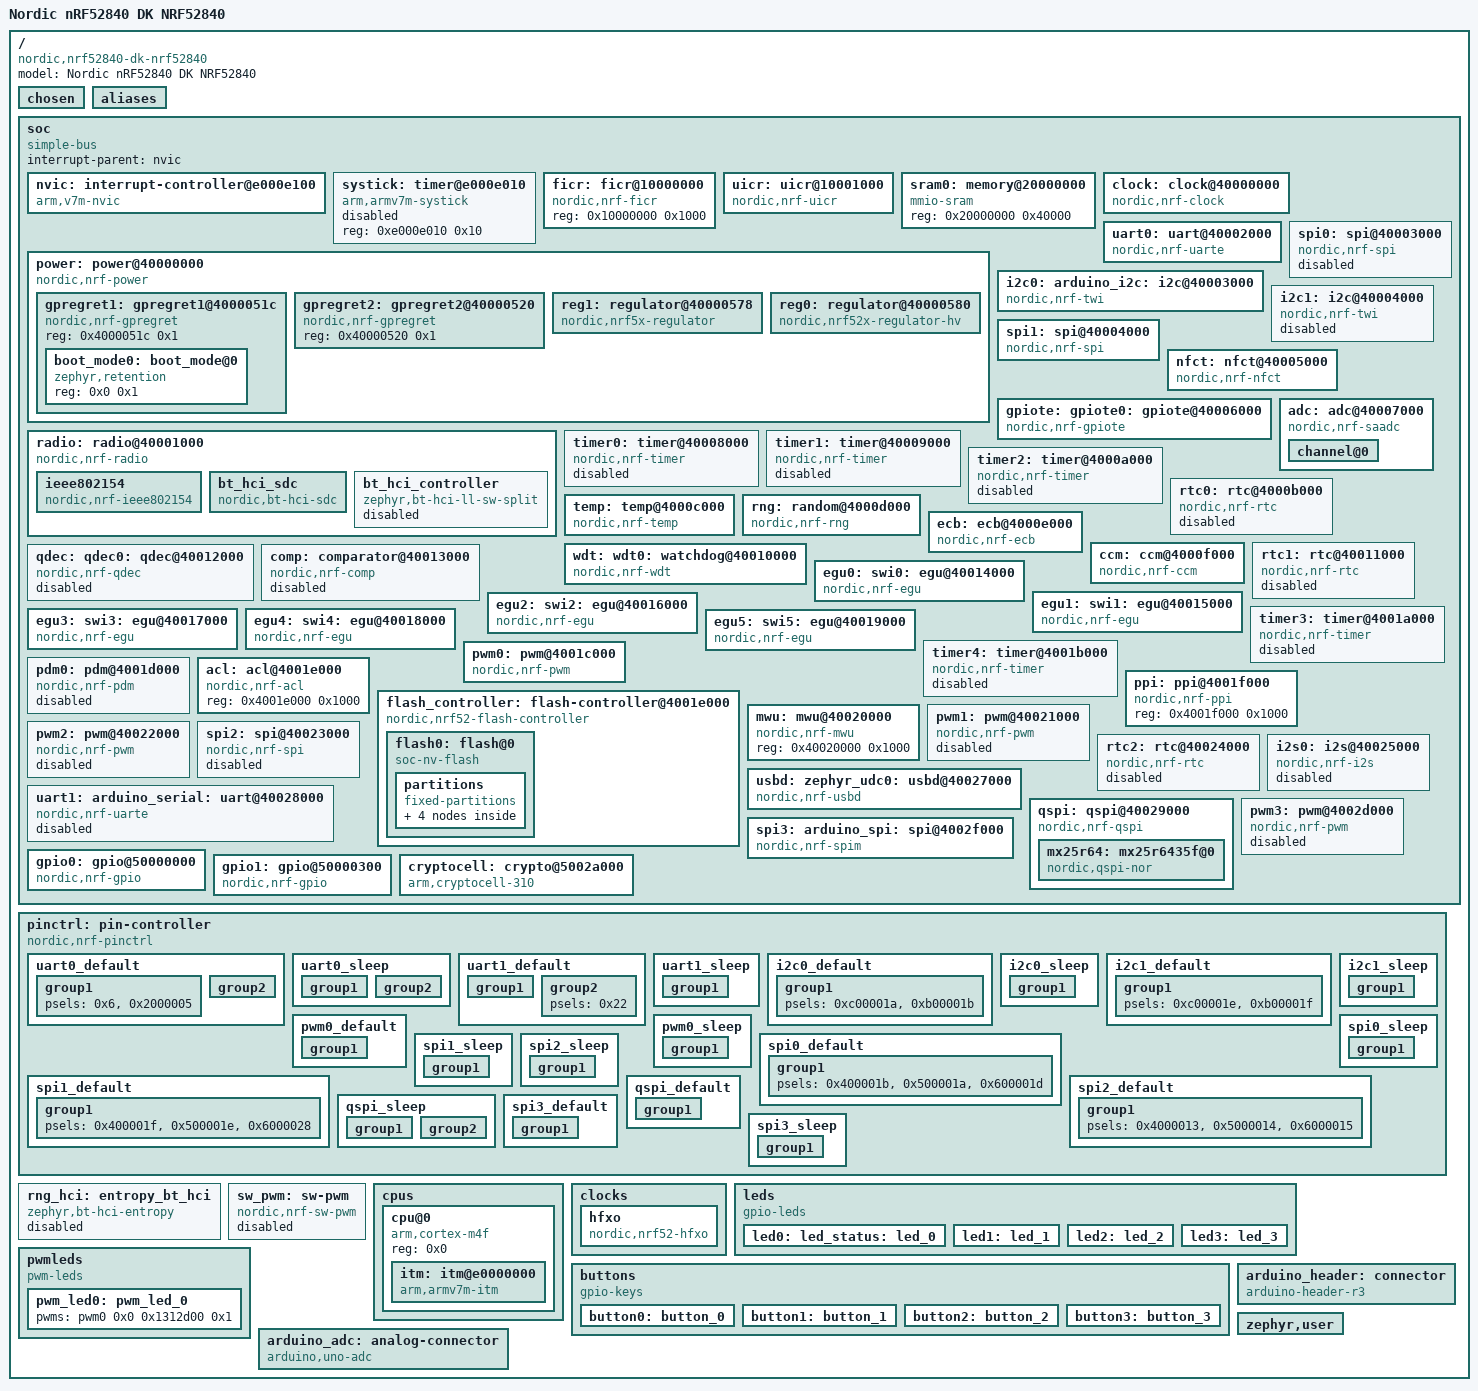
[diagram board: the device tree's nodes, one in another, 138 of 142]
/dts-v1/;

/* node '/' defined in zephyr\dts\common\skeleton.dtsi:9 */
/ {
	#address-cells = < 0x1 >;                   /* in zephyr\dts\common\skeleton.dtsi:10 */
	#size-cells = < 0x1 >;                      /* in zephyr\dts\common\skeleton.dtsi:11 */
	model = "Nordic nRF52840 DK NRF52840";      /* in zephyr\boards\nordic\nrf52840dk\nrf52840dk_nrf52840.dts:15 */
	compatible = "nordic,nrf52840-dk-nrf52840"; /* in zephyr\boards\nordic\nrf52840dk\nrf52840dk_nrf52840.dts:16 */

	/* node '/chosen' defined in zephyr\dts\common\skeleton.dtsi:13 */
	chosen {
		zephyr,bt-hci = &bt_hci_sdc;                 /* in zephyr\dts\arm\nordic\nrf52840.dtsi:14 */
		zephyr,entropy = &cryptocell;                /* in zephyr\dts\arm\nordic\nrf52840.dtsi:15 */
		zephyr,flash-controller = &flash_controller; /* in zephyr\dts\arm\nordic\nrf52840.dtsi:16 */
		zephyr,sram = &sram0;                        /* in zephyr\dts\vendor\nordic\nrf52840_partition.dtsi:9 */
		zephyr,flash = &flash0;                      /* in zephyr\dts\vendor\nordic\nrf52840_partition.dtsi:10 */
		zephyr,code-partition = &slot0_partition;    /* in zephyr\dts\vendor\nordic\nrf52840_partition.dtsi:11 */
		zephyr,console = &uart0;                     /* in zephyr\boards\nordic\nrf52840dk\nrf52840dk_nrf52840.dts:19 */
		zephyr,shell-uart = &uart0;                  /* in zephyr\boards\nordic\nrf52840dk\nrf52840dk_nrf52840.dts:20 */
		zephyr,uart-mcumgr = &uart0;                 /* in zephyr\boards\nordic\nrf52840dk\nrf52840dk_nrf52840.dts:21 */
		zephyr,bt-mon-uart = &uart0;                 /* in zephyr\boards\nordic\nrf52840dk\nrf52840dk_nrf52840.dts:22 */
		zephyr,bt-c2h-uart = &uart0;                 /* in zephyr\boards\nordic\nrf52840dk\nrf52840dk_nrf52840.dts:23 */
		zephyr,ieee802154 = &ieee802154;             /* in zephyr\boards\nordic\nrf52840dk\nrf52840dk_nrf52840.dts:24 */
		zephyr,boot-mode = &boot_mode0;              /* in zephyr\boards\nordic\nrf52840dk\nrf52840dk_nrf52840.dts:25 */
	};

	/* node '/aliases' defined in zephyr\dts\common\skeleton.dtsi:15 */
	aliases {
		led0 = &led0;               /* in zephyr\boards\nordic\nrf52840dk\nrf52840dk_nrf52840.dts:130 */
		led1 = &led1;               /* in zephyr\boards\nordic\nrf52840dk\nrf52840dk_nrf52840.dts:131 */
		led2 = &led2;               /* in zephyr\boards\nordic\nrf52840dk\nrf52840dk_nrf52840.dts:132 */
		led3 = &led3;               /* in zephyr\boards\nordic\nrf52840dk\nrf52840dk_nrf52840.dts:133 */
		pwm-led0 = &pwm_led0;       /* in zephyr\boards\nordic\nrf52840dk\nrf52840dk_nrf52840.dts:134 */
		sw0 = &button0;             /* in zephyr\boards\nordic\nrf52840dk\nrf52840dk_nrf52840.dts:135 */
		sw1 = &button1;             /* in zephyr\boards\nordic\nrf52840dk\nrf52840dk_nrf52840.dts:136 */
		sw2 = &button2;             /* in zephyr\boards\nordic\nrf52840dk\nrf52840dk_nrf52840.dts:137 */
		sw3 = &button3;             /* in zephyr\boards\nordic\nrf52840dk\nrf52840dk_nrf52840.dts:138 */
		mcuboot-button0 = &button0; /* in zephyr\boards\nordic\nrf52840dk\nrf52840dk_nrf52840.dts:139 */
		mcuboot-led0 = &led0;       /* in zephyr\boards\nordic\nrf52840dk\nrf52840dk_nrf52840.dts:140 */
		watchdog0 = &wdt0;          /* in zephyr\boards\nordic\nrf52840dk\nrf52840dk_nrf52840.dts:141 */
		led-status = &led_status;   /* in ..\..\Users\willh\Desktop\Fish_monitor\aquatic_biomonitor_fw\boards\nrf52840dk_nrf52840.overlay:16 */
	};

	/* node '/soc' defined in zephyr\dts\arm\armv7-m.dtsi:6 */
	soc {
		#address-cells = < 0x1 >;     /* in zephyr\dts\arm\armv7-m.dtsi:7 */
		#size-cells = < 0x1 >;        /* in zephyr\dts\arm\armv7-m.dtsi:8 */
		interrupt-parent = < &nvic >; /* in zephyr\dts\arm\armv7-m.dtsi:10 */
		ranges;                       /* in zephyr\dts\arm\armv7-m.dtsi:11 */
		compatible = "simple-bus";    /* in zephyr\dts\arm\nordic\nrf52840.dtsi:48 */

		/* node '/soc/interrupt-controller@e000e100' defined in zephyr\dts\arm\armv7-m.dtsi:13 */
		nvic: interrupt-controller@e000e100 {
			#address-cells = < 0x1 >;            /* in zephyr\dts\arm\armv7-m.dtsi:14 */
			compatible = "arm,v7m-nvic";         /* in zephyr\dts\arm\armv7-m.dtsi:15 */
			reg = < 0xe000e100 0xc00 >;          /* in zephyr\dts\arm\armv7-m.dtsi:16 */
			interrupt-controller;                /* in zephyr\dts\arm\armv7-m.dtsi:17 */
			#interrupt-cells = < 0x2 >;          /* in zephyr\dts\arm\armv7-m.dtsi:18 */
			arm,num-irq-priority-bits = < 0x3 >; /* in zephyr\dts\arm\nordic\nrf52840.dtsi:599 */
			phandle = < 0x1 >;                   /* in zephyr\dts\arm\armv7-m.dtsi:10 */
		};

		/* node '/soc/timer@e000e010' defined in zephyr\dts\arm\armv7-m.dtsi:21 */
		systick: timer@e000e010 {
			compatible = "arm,armv7m-systick"; /* in zephyr\dts\arm\armv7-m.dtsi:22 */
			reg = < 0xe000e010 0x10 >;         /* in zephyr\dts\arm\armv7-m.dtsi:23 */
			status = "disabled";               /* in zephyr\dts\arm\nordic\nrf52840.dtsi:604 */
		};

		/* node '/soc/ficr@10000000' defined in zephyr\dts\arm\nordic\nrf52840.dtsi:50 */
		ficr: ficr@10000000 {
			compatible = "nordic,nrf-ficr"; /* in zephyr\dts\arm\nordic\nrf52840.dtsi:51 */
			reg = < 0x10000000 0x1000 >;    /* in zephyr\dts\arm\nordic\nrf52840.dtsi:52 */
			#nordic,ficr-cells = < 0x1 >;   /* in zephyr\dts\arm\nordic\nrf52840.dtsi:53 */
			status = "okay";                /* in zephyr\dts\arm\nordic\nrf52840.dtsi:54 */
		};

		/* node '/soc/uicr@10001000' defined in zephyr\dts\arm\nordic\nrf52840.dtsi:57 */
		uicr: uicr@10001000 {
			compatible = "nordic,nrf-uicr";     /* in zephyr\dts\arm\nordic\nrf52840.dtsi:58 */
			reg = < 0x10001000 0x1000 >;        /* in zephyr\dts\arm\nordic\nrf52840.dtsi:59 */
			ranges = < 0x0 0x10001000 0x1000 >; /* in zephyr\dts\arm\nordic\nrf52840.dtsi:60 */
			status = "okay";                    /* in zephyr\dts\arm\nordic\nrf52840.dtsi:61 */
			#address-cells = < 0x1 >;           /* in zephyr\dts\arm\nordic\nrf52840.dtsi:62 */
			#size-cells = < 0x1 >;              /* in zephyr\dts\arm\nordic\nrf52840.dtsi:63 */
			gpio-as-nreset;                     /* in zephyr\boards\nordic\nrf52840dk\nrf52840dk_nrf52840.dts:158 */
		};

		/* node '/soc/memory@20000000' defined in zephyr\dts\arm\nordic\nrf52840.dtsi:66 */
		sram0: memory@20000000 {
			compatible = "mmio-sram";            /* in zephyr\dts\arm\nordic\nrf52840.dtsi:67 */
			reg = < 0x20000000 0x40000 >;        /* in zephyr\dts\arm\nordic\nrf52840.dtsi:68 */
			ranges = < 0x0 0x20000000 0x40000 >; /* in zephyr\dts\arm\nordic\nrf52840.dtsi:69 */
			#address-cells = < 0x1 >;            /* in zephyr\dts\arm\nordic\nrf52840.dtsi:70 */
			#size-cells = < 0x1 >;               /* in zephyr\dts\arm\nordic\nrf52840.dtsi:71 */
		};

		/* node '/soc/clock@40000000' defined in zephyr\dts\arm\nordic\nrf52840.dtsi:74 */
		clock: clock@40000000 {
			compatible = "nordic,nrf-clock"; /* in zephyr\dts\arm\nordic\nrf52840.dtsi:75 */
			reg = < 0x40000000 0x1000 >;     /* in zephyr\dts\arm\nordic\nrf52840.dtsi:76 */
			interrupts = < 0x0 0x1 >;        /* in zephyr\dts\arm\nordic\nrf52840.dtsi:77 */
			status = "okay";                 /* in zephyr\dts\arm\nordic\nrf52840.dtsi:78 */
		};

		/* node '/soc/power@40000000' defined in zephyr\dts\arm\nordic\nrf52840.dtsi:81 */
		power: power@40000000 {
			compatible = "nordic,nrf-power"; /* in zephyr\dts\arm\nordic\nrf52840.dtsi:82 */
			reg = < 0x40000000 0x1000 >;     /* in zephyr\dts\arm\nordic\nrf52840.dtsi:83 */
			interrupts = < 0x0 0x1 >;        /* in zephyr\dts\arm\nordic\nrf52840.dtsi:84 */
			status = "okay";                 /* in zephyr\dts\arm\nordic\nrf52840.dtsi:85 */
			#address-cells = < 0x1 >;        /* in zephyr\dts\arm\nordic\nrf52840.dtsi:86 */
			#size-cells = < 0x1 >;           /* in zephyr\dts\arm\nordic\nrf52840.dtsi:87 */

			/* node '/soc/power@40000000/gpregret1@4000051c' defined in zephyr\dts\arm\nordic\nrf52840.dtsi:89 */
			gpregret1: gpregret1@4000051c {
				#address-cells = < 0x1 >;           /* in zephyr\dts\arm\nordic\nrf52840.dtsi:90 */
				#size-cells = < 0x1 >;              /* in zephyr\dts\arm\nordic\nrf52840.dtsi:91 */
				compatible = "nordic,nrf-gpregret"; /* in zephyr\dts\arm\nordic\nrf52840.dtsi:92 */
				reg = < 0x4000051c 0x1 >;           /* in zephyr\dts\arm\nordic\nrf52840.dtsi:93 */
				status = "okay";                    /* in zephyr\boards\nordic\nrf52840dk\nrf52840dk_nrf52840.dts:294 */

				/* node '/soc/power@40000000/gpregret1@4000051c/boot_mode@0' defined in zephyr\boards\nordic\nrf52840dk\nrf52840dk_nrf52840.dts:296 */
				boot_mode0: boot_mode@0 {
					compatible = "zephyr,retention"; /* in zephyr\boards\nordic\nrf52840dk\nrf52840dk_nrf52840.dts:297 */
					status = "okay";                 /* in zephyr\boards\nordic\nrf52840dk\nrf52840dk_nrf52840.dts:298 */
					reg = < 0x0 0x1 >;               /* in zephyr\boards\nordic\nrf52840dk\nrf52840dk_nrf52840.dts:299 */
				};
			};

			/* node '/soc/power@40000000/gpregret2@40000520' defined in zephyr\dts\arm\nordic\nrf52840.dtsi:97 */
			gpregret2: gpregret2@40000520 {
				#address-cells = < 0x1 >;           /* in zephyr\dts\arm\nordic\nrf52840.dtsi:98 */
				#size-cells = < 0x1 >;              /* in zephyr\dts\arm\nordic\nrf52840.dtsi:99 */
				compatible = "nordic,nrf-gpregret"; /* in zephyr\dts\arm\nordic\nrf52840.dtsi:100 */
				reg = < 0x40000520 0x1 >;           /* in zephyr\dts\arm\nordic\nrf52840.dtsi:101 */
				status = "okay";                    /* in zephyr\dts\arm\nordic\nrf52840.dtsi:102 */
			};

			/* node '/soc/power@40000000/regulator@40000578' defined in zephyr\dts\arm\nordic\nrf52840.dtsi:105 */
			reg1: regulator@40000578 {
				compatible = "nordic,nrf5x-regulator"; /* in zephyr\dts\arm\nordic\nrf52840.dtsi:106 */
				reg = < 0x40000578 0x1 >;              /* in zephyr\dts\arm\nordic\nrf52840.dtsi:107 */
				regulator-name = "REG1";               /* in zephyr\dts\arm\nordic\nrf52840.dtsi:108 */
				regulator-initial-mode = < 0x1 >;      /* in zephyr\boards\nordic\nrf52840dk\nrf52840dk_nrf52840.dts:150 */
			};

			/* node '/soc/power@40000000/regulator@40000580' defined in zephyr\dts\arm\nordic\nrf52840_qiaa.dtsi:11 */
			reg0: regulator@40000580 {
				compatible = "nordic,nrf52x-regulator-hv"; /* in zephyr\dts\arm\nordic\nrf52840_qiaa.dtsi:12 */
				reg = < 0x40000580 0x1 >;                  /* in zephyr\dts\arm\nordic\nrf52840_qiaa.dtsi:13 */
				regulator-name = "REG0";                   /* in zephyr\dts\arm\nordic\nrf52840_qiaa.dtsi:14 */
				status = "okay";                           /* in zephyr\boards\nordic\nrf52840dk\nrf52840dk_nrf52840.dts:146 */
			};
		};

		/* node '/soc/radio@40001000' defined in zephyr\dts\arm\nordic\nrf52840.dtsi:113 */
		radio: radio@40001000 {
			compatible = "nordic,nrf-radio"; /* in zephyr\dts\arm\nordic\nrf52840.dtsi:114 */
			reg = < 0x40001000 0x1000 >;     /* in zephyr\dts\arm\nordic\nrf52840.dtsi:115 */
			interrupts = < 0x1 0x1 >;        /* in zephyr\dts\arm\nordic\nrf52840.dtsi:116 */
			status = "okay";                 /* in zephyr\dts\arm\nordic\nrf52840.dtsi:117 */
			ieee802154-supported;            /* in zephyr\dts\arm\nordic\nrf52840.dtsi:118 */
			ble-2mbps-supported;             /* in zephyr\dts\arm\nordic\nrf52840.dtsi:119 */
			ble-coded-phy-supported;         /* in zephyr\dts\arm\nordic\nrf52840.dtsi:120 */
			radio-tx-high-power-supported;   /* in zephyr\dts\arm\nordic\nrf52840.dtsi:121 */

			/* node '/soc/radio@40001000/ieee802154' defined in zephyr\dts\arm\nordic\nrf52840.dtsi:123 */
			ieee802154: ieee802154 {
				compatible = "nordic,nrf-ieee802154"; /* in zephyr\dts\arm\nordic\nrf52840.dtsi:124 */
				status = "okay";                      /* in zephyr\boards\nordic\nrf52840dk\nrf52840dk_nrf52840.dts:285 */
			};

			/* node '/soc/radio@40001000/bt_hci_sdc' defined in zephyr\dts\arm\nordic\nrf52840.dtsi:128 */
			bt_hci_sdc: bt_hci_sdc {
				compatible = "nordic,bt-hci-sdc"; /* in zephyr\dts\arm\nordic\nrf52840.dtsi:129 */
				status = "okay";                  /* in zephyr\dts\arm\nordic\nrf52840.dtsi:130 */
			};

			/* node '/soc/radio@40001000/bt_hci_controller' defined in zephyr\dts\arm\nordic\nrf52840.dtsi:132 */
			bt_hci_controller: bt_hci_controller {
				compatible = "zephyr,bt-hci-ll-sw-split"; /* in zephyr\dts\arm\nordic\nrf52840.dtsi:133 */
				status = "disabled";                      /* in zephyr\dts\arm\nordic\nrf52840.dtsi:134 */
			};
		};

		/* node '/soc/uart@40002000' defined in zephyr\dts\arm\nordic\nrf52840.dtsi:138 */
		uart0: uart@40002000 {
			reg = < 0x40002000 0x1000 >;     /* in zephyr\dts\arm\nordic\nrf52840.dtsi:142 */
			interrupts = < 0x2 0x1 >;        /* in zephyr\dts\arm\nordic\nrf52840.dtsi:143 */
			compatible = "nordic,nrf-uarte"; /* in zephyr\boards\nordic\nrf52840dk\nrf52840dk_nrf52840.dts:186 */
			status = "okay";                 /* in zephyr\boards\nordic\nrf52840dk\nrf52840dk_nrf52840.dts:187 */
			current-speed = < 0x1c200 >;     /* in zephyr\boards\nordic\nrf52840dk\nrf52840dk_nrf52840.dts:188 */
			pinctrl-0 = < &uart0_default >;  /* in zephyr\boards\nordic\nrf52840dk\nrf52840dk_nrf52840.dts:189 */
			pinctrl-1 = < &uart0_sleep >;    /* in zephyr\boards\nordic\nrf52840dk\nrf52840dk_nrf52840.dts:190 */
			pinctrl-names = "default",
			                "sleep";         /* in zephyr\boards\nordic\nrf52840dk\nrf52840dk_nrf52840.dts:191 */
		};

		/* node '/soc/i2c@40003000' defined in zephyr\dts\arm\nordic\nrf52840.dtsi:147 */
		i2c0: arduino_i2c: i2c@40003000 {
			#address-cells = < 0x1 >;       /* in zephyr\dts\arm\nordic\nrf52840.dtsi:156 */
			#size-cells = < 0x0 >;          /* in zephyr\dts\arm\nordic\nrf52840.dtsi:157 */
			reg = < 0x40003000 0x1000 >;    /* in zephyr\dts\arm\nordic\nrf52840.dtsi:158 */
			interrupts = < 0x3 0x1 >;       /* in zephyr\dts\arm\nordic\nrf52840.dtsi:159 */
			easydma-maxcnt-bits = < 0x10 >; /* in zephyr\dts\arm\nordic\nrf52840.dtsi:160 */
			zephyr,pm-device-runtime-auto;  /* in zephyr\dts\arm\nordic\nrf52840.dtsi:162 */
			compatible = "nordic,nrf-twi";  /* in zephyr\boards\nordic\nrf52840dk\nrf52840dk_nrf52840.dts:202 */
			status = "okay";                /* in zephyr\boards\nordic\nrf52840dk\nrf52840dk_nrf52840.dts:203 */
			pinctrl-0 = < &i2c0_default >;  /* in zephyr\boards\nordic\nrf52840dk\nrf52840dk_nrf52840.dts:204 */
			pinctrl-1 = < &i2c0_sleep >;    /* in zephyr\boards\nordic\nrf52840dk\nrf52840dk_nrf52840.dts:205 */
			pinctrl-names = "default",
			                "sleep";        /* in zephyr\boards\nordic\nrf52840dk\nrf52840dk_nrf52840.dts:206 */
		};

		/* node '/soc/spi@40003000' defined in zephyr\dts\arm\nordic\nrf52840.dtsi:165 */
		spi0: spi@40003000 {
			#address-cells = < 0x1 >;       /* in zephyr\dts\arm\nordic\nrf52840.dtsi:174 */
			#size-cells = < 0x0 >;          /* in zephyr\dts\arm\nordic\nrf52840.dtsi:175 */
			reg = < 0x40003000 0x1000 >;    /* in zephyr\dts\arm\nordic\nrf52840.dtsi:176 */
			interrupts = < 0x3 0x1 >;       /* in zephyr\dts\arm\nordic\nrf52840.dtsi:177 */
			max-frequency = < 0x7a1200 >;   /* in zephyr\dts\arm\nordic\nrf52840.dtsi:178 */
			easydma-maxcnt-bits = < 0x10 >; /* in zephyr\dts\arm\nordic\nrf52840.dtsi:179 */
			status = "disabled";            /* in zephyr\dts\arm\nordic\nrf52840.dtsi:180 */
			compatible = "nordic,nrf-spi";  /* in zephyr\boards\nordic\nrf52840dk\nrf52840dk_nrf52840.dts:226 */
			pinctrl-0 = < &spi0_default >;  /* in zephyr\boards\nordic\nrf52840dk\nrf52840dk_nrf52840.dts:229 */
			pinctrl-1 = < &spi0_sleep >;    /* in zephyr\boards\nordic\nrf52840dk\nrf52840dk_nrf52840.dts:230 */
			pinctrl-names = "default",
			                "sleep";        /* in zephyr\boards\nordic\nrf52840dk\nrf52840dk_nrf52840.dts:231 */
		};

		/* node '/soc/i2c@40004000' defined in zephyr\dts\arm\nordic\nrf52840.dtsi:183 */
		i2c1: i2c@40004000 {
			#address-cells = < 0x1 >;       /* in zephyr\dts\arm\nordic\nrf52840.dtsi:192 */
			#size-cells = < 0x0 >;          /* in zephyr\dts\arm\nordic\nrf52840.dtsi:193 */
			reg = < 0x40004000 0x1000 >;    /* in zephyr\dts\arm\nordic\nrf52840.dtsi:194 */
			interrupts = < 0x4 0x1 >;       /* in zephyr\dts\arm\nordic\nrf52840.dtsi:195 */
			easydma-maxcnt-bits = < 0x10 >; /* in zephyr\dts\arm\nordic\nrf52840.dtsi:196 */
			status = "disabled";            /* in zephyr\dts\arm\nordic\nrf52840.dtsi:197 */
			zephyr,pm-device-runtime-auto;  /* in zephyr\dts\arm\nordic\nrf52840.dtsi:198 */
			compatible = "nordic,nrf-twi";  /* in zephyr\boards\nordic\nrf52840dk\nrf52840dk_nrf52840.dts:210 */
			pinctrl-0 = < &i2c1_default >;  /* in zephyr\boards\nordic\nrf52840dk\nrf52840dk_nrf52840.dts:213 */
			pinctrl-1 = < &i2c1_sleep >;    /* in zephyr\boards\nordic\nrf52840dk\nrf52840dk_nrf52840.dts:214 */
			pinctrl-names = "default",
			                "sleep";        /* in zephyr\boards\nordic\nrf52840dk\nrf52840dk_nrf52840.dts:215 */
		};

		/* node '/soc/spi@40004000' defined in zephyr\dts\arm\nordic\nrf52840.dtsi:201 */
		spi1: spi@40004000 {
			#address-cells = < 0x1 >;       /* in zephyr\dts\arm\nordic\nrf52840.dtsi:210 */
			#size-cells = < 0x0 >;          /* in zephyr\dts\arm\nordic\nrf52840.dtsi:211 */
			reg = < 0x40004000 0x1000 >;    /* in zephyr\dts\arm\nordic\nrf52840.dtsi:212 */
			interrupts = < 0x4 0x1 >;       /* in zephyr\dts\arm\nordic\nrf52840.dtsi:213 */
			max-frequency = < 0x7a1200 >;   /* in zephyr\dts\arm\nordic\nrf52840.dtsi:214 */
			easydma-maxcnt-bits = < 0x10 >; /* in zephyr\dts\arm\nordic\nrf52840.dtsi:215 */
			compatible = "nordic,nrf-spi";  /* in zephyr\boards\nordic\nrf52840dk\nrf52840dk_nrf52840.dts:235 */
			status = "okay";                /* in zephyr\boards\nordic\nrf52840dk\nrf52840dk_nrf52840.dts:236 */
			pinctrl-0 = < &spi1_default >;  /* in zephyr\boards\nordic\nrf52840dk\nrf52840dk_nrf52840.dts:237 */
			pinctrl-1 = < &spi1_sleep >;    /* in zephyr\boards\nordic\nrf52840dk\nrf52840dk_nrf52840.dts:238 */
			pinctrl-names = "default",
			                "sleep";        /* in zephyr\boards\nordic\nrf52840dk\nrf52840dk_nrf52840.dts:239 */
		};

		/* node '/soc/nfct@40005000' defined in zephyr\dts\arm\nordic\nrf52840.dtsi:219 */
		nfct: nfct@40005000 {
			compatible = "nordic,nrf-nfct"; /* in zephyr\dts\arm\nordic\nrf52840.dtsi:220 */
			reg = < 0x40005000 0x1000 >;    /* in zephyr\dts\arm\nordic\nrf52840.dtsi:221 */
			interrupts = < 0x5 0x1 >;       /* in zephyr\dts\arm\nordic\nrf52840.dtsi:222 */
			status = "okay";                /* in zephyr\boards\nordic\nrf52840dk\nrf52840dk_nrf52840.dts:166 */
		};

		/* node '/soc/gpiote@40006000' defined in zephyr\dts\arm\nordic\nrf52840.dtsi:226 */
		gpiote: gpiote0: gpiote@40006000 {
			compatible = "nordic,nrf-gpiote"; /* in zephyr\dts\arm\nordic\nrf52840.dtsi:227 */
			reg = < 0x40006000 0x1000 >;      /* in zephyr\dts\arm\nordic\nrf52840.dtsi:228 */
			interrupts = < 0x6 0x5 >;         /* in zephyr\dts\arm\nordic\nrf52840.dtsi:229 */
			instance = < 0x0 >;               /* in zephyr\dts\arm\nordic\nrf52840.dtsi:231 */
			status = "okay";                  /* in zephyr\boards\nordic\nrf52840dk\nrf52840dk_nrf52840.dts:162 */
			phandle = < 0x17 >;               /* in zephyr\dts\arm\nordic\nrf52840.dtsi:573 */
		};

		/* node '/soc/adc@40007000' defined in zephyr\dts\arm\nordic\nrf52840.dtsi:234 */
		adc: adc@40007000 {
			compatible = "nordic,nrf-saadc"; /* in zephyr\dts\arm\nordic\nrf52840.dtsi:235 */
			reg = < 0x40007000 0x1000 >;     /* in zephyr\dts\arm\nordic\nrf52840.dtsi:236 */
			interrupts = < 0x7 0x1 >;        /* in zephyr\dts\arm\nordic\nrf52840.dtsi:237 */
			#io-channel-cells = < 0x1 >;     /* in zephyr\dts\arm\nordic\nrf52840.dtsi:239 */
			zephyr,pm-device-runtime-auto;   /* in zephyr\dts\arm\nordic\nrf52840.dtsi:240 */
			status = "okay";                 /* in ..\..\Users\willh\Desktop\Fish_monitor\aquatic_biomonitor_fw\boards\nrf52840dk_nrf52840.overlay:21 */
			#address-cells = < 0x1 >;        /* in ..\..\Users\willh\Desktop\Fish_monitor\aquatic_biomonitor_fw\boards\nrf52840dk_nrf52840.overlay:22 */
			#size-cells = < 0x0 >;           /* in ..\..\Users\willh\Desktop\Fish_monitor\aquatic_biomonitor_fw\boards\nrf52840dk_nrf52840.overlay:23 */
			phandle = < 0x1c >;              /* in zephyr\boards\nordic\nrf52840dk\nrf52840dk_nrf52840.dts:120 */

			/* node '/soc/adc@40007000/channel@0' defined in ..\..\Users\willh\Desktop\Fish_monitor\aquatic_biomonitor_fw\boards\nrf52840dk_nrf52840.overlay:25 */
			channel@0 {
				reg = < 0x0 >;                         /* in ..\..\Users\willh\Desktop\Fish_monitor\aquatic_biomonitor_fw\boards\nrf52840dk_nrf52840.overlay:26 */
				zephyr,gain = "ADC_GAIN_1_6";          /* in ..\..\Users\willh\Desktop\Fish_monitor\aquatic_biomonitor_fw\boards\nrf52840dk_nrf52840.overlay:27 */
				zephyr,reference = "ADC_REF_INTERNAL"; /* in ..\..\Users\willh\Desktop\Fish_monitor\aquatic_biomonitor_fw\boards\nrf52840dk_nrf52840.overlay:28 */
				zephyr,acquisition-time = < 0x4028 >;  /* in ..\..\Users\willh\Desktop\Fish_monitor\aquatic_biomonitor_fw\boards\nrf52840dk_nrf52840.overlay:29 */
				zephyr,input-positive = < 0x0 >;       /* in ..\..\Users\willh\Desktop\Fish_monitor\aquatic_biomonitor_fw\boards\nrf52840dk_nrf52840.overlay:30 */
				zephyr,resolution = < 0xc >;           /* in ..\..\Users\willh\Desktop\Fish_monitor\aquatic_biomonitor_fw\boards\nrf52840dk_nrf52840.overlay:31 */
				zephyr,oversampling = < 0x4 >;         /* in ..\..\Users\willh\Desktop\Fish_monitor\aquatic_biomonitor_fw\boards\nrf52840dk_nrf52840.overlay:32 */
			};
		};

		/* node '/soc/timer@40008000' defined in zephyr\dts\arm\nordic\nrf52840.dtsi:243 */
		timer0: timer@40008000 {
			compatible = "nordic,nrf-timer"; /* in zephyr\dts\arm\nordic\nrf52840.dtsi:244 */
			status = "disabled";             /* in zephyr\dts\arm\nordic\nrf52840.dtsi:245 */
			reg = < 0x40008000 0x1000 >;     /* in zephyr\dts\arm\nordic\nrf52840.dtsi:246 */
			cc-num = < 0x4 >;                /* in zephyr\dts\arm\nordic\nrf52840.dtsi:247 */
			max-bit-width = < 0x20 >;        /* in zephyr\dts\arm\nordic\nrf52840.dtsi:248 */
			interrupts = < 0x8 0x1 >;        /* in zephyr\dts\arm\nordic\nrf52840.dtsi:249 */
			prescaler = < 0x0 >;             /* in zephyr\dts\arm\nordic\nrf52840.dtsi:250 */
		};

		/* node '/soc/timer@40009000' defined in zephyr\dts\arm\nordic\nrf52840.dtsi:253 */
		timer1: timer@40009000 {
			compatible = "nordic,nrf-timer"; /* in zephyr\dts\arm\nordic\nrf52840.dtsi:254 */
			status = "disabled";             /* in zephyr\dts\arm\nordic\nrf52840.dtsi:255 */
			reg = < 0x40009000 0x1000 >;     /* in zephyr\dts\arm\nordic\nrf52840.dtsi:256 */
			cc-num = < 0x4 >;                /* in zephyr\dts\arm\nordic\nrf52840.dtsi:257 */
			max-bit-width = < 0x20 >;        /* in zephyr\dts\arm\nordic\nrf52840.dtsi:258 */
			interrupts = < 0x9 0x1 >;        /* in zephyr\dts\arm\nordic\nrf52840.dtsi:259 */
			prescaler = < 0x0 >;             /* in zephyr\dts\arm\nordic\nrf52840.dtsi:260 */
			phandle = < 0x18 >;              /* in zephyr\dts\vendor\nordic\nrf_common.dtsi:42 */
		};

		/* node '/soc/timer@4000a000' defined in zephyr\dts\arm\nordic\nrf52840.dtsi:263 */
		timer2: timer@4000a000 {
			compatible = "nordic,nrf-timer"; /* in zephyr\dts\arm\nordic\nrf52840.dtsi:264 */
			status = "disabled";             /* in zephyr\dts\arm\nordic\nrf52840.dtsi:265 */
			reg = < 0x4000a000 0x1000 >;     /* in zephyr\dts\arm\nordic\nrf52840.dtsi:266 */
			cc-num = < 0x4 >;                /* in zephyr\dts\arm\nordic\nrf52840.dtsi:267 */
			max-bit-width = < 0x20 >;        /* in zephyr\dts\arm\nordic\nrf52840.dtsi:268 */
			interrupts = < 0xa 0x1 >;        /* in zephyr\dts\arm\nordic\nrf52840.dtsi:269 */
			prescaler = < 0x0 >;             /* in zephyr\dts\arm\nordic\nrf52840.dtsi:270 */
		};

		/* node '/soc/rtc@4000b000' defined in zephyr\dts\arm\nordic\nrf52840.dtsi:273 */
		rtc0: rtc@4000b000 {
			compatible = "nordic,nrf-rtc"; /* in zephyr\dts\arm\nordic\nrf52840.dtsi:274 */
			reg = < 0x4000b000 0x1000 >;   /* in zephyr\dts\arm\nordic\nrf52840.dtsi:275 */
			cc-num = < 0x3 >;              /* in zephyr\dts\arm\nordic\nrf52840.dtsi:276 */
			interrupts = < 0xb 0x1 >;      /* in zephyr\dts\arm\nordic\nrf52840.dtsi:277 */
			status = "disabled";           /* in zephyr\dts\arm\nordic\nrf52840.dtsi:278 */
			clock-frequency = < 0x8000 >;  /* in zephyr\dts\arm\nordic\nrf52840.dtsi:279 */
			prescaler = < 0x1 >;           /* in zephyr\dts\arm\nordic\nrf52840.dtsi:280 */
		};

		/* node '/soc/temp@4000c000' defined in zephyr\dts\arm\nordic\nrf52840.dtsi:283 */
		temp: temp@4000c000 {
			compatible = "nordic,nrf-temp"; /* in zephyr\dts\arm\nordic\nrf52840.dtsi:284 */
			reg = < 0x4000c000 0x1000 >;    /* in zephyr\dts\arm\nordic\nrf52840.dtsi:285 */
			interrupts = < 0xc 0x1 >;       /* in zephyr\dts\arm\nordic\nrf52840.dtsi:286 */
			status = "okay";                /* in zephyr\dts\arm\nordic\nrf52840.dtsi:287 */
		};

		/* node '/soc/random@4000d000' defined in zephyr\dts\arm\nordic\nrf52840.dtsi:290 */
		rng: random@4000d000 {
			compatible = "nordic,nrf-rng"; /* in zephyr\dts\arm\nordic\nrf52840.dtsi:291 */
			reg = < 0x4000d000 0x1000 >;   /* in zephyr\dts\arm\nordic\nrf52840.dtsi:292 */
			interrupts = < 0xd 0x1 >;      /* in zephyr\dts\arm\nordic\nrf52840.dtsi:293 */
			status = "okay";               /* in zephyr\dts\arm\nordic\nrf52840.dtsi:294 */
		};

		/* node '/soc/ecb@4000e000' defined in zephyr\dts\arm\nordic\nrf52840.dtsi:297 */
		ecb: ecb@4000e000 {
			compatible = "nordic,nrf-ecb"; /* in zephyr\dts\arm\nordic\nrf52840.dtsi:298 */
			reg = < 0x4000e000 0x1000 >;   /* in zephyr\dts\arm\nordic\nrf52840.dtsi:299 */
			interrupts = < 0xe 0x1 >;      /* in zephyr\dts\arm\nordic\nrf52840.dtsi:300 */
			status = "okay";               /* in zephyr\dts\arm\nordic\nrf52840.dtsi:301 */
		};

		/* node '/soc/ccm@4000f000' defined in zephyr\dts\arm\nordic\nrf52840.dtsi:304 */
		ccm: ccm@4000f000 {
			compatible = "nordic,nrf-ccm"; /* in zephyr\dts\arm\nordic\nrf52840.dtsi:305 */
			reg = < 0x4000f000 0x1000 >;   /* in zephyr\dts\arm\nordic\nrf52840.dtsi:306 */
			interrupts = < 0xf 0x1 >;      /* in zephyr\dts\arm\nordic\nrf52840.dtsi:307 */
			length-field-length-8-bits;    /* in zephyr\dts\arm\nordic\nrf52840.dtsi:308 */
			status = "okay";               /* in zephyr\dts\arm\nordic\nrf52840.dtsi:309 */
		};

		/* node '/soc/watchdog@40010000' defined in zephyr\dts\arm\nordic\nrf52840.dtsi:312 */
		wdt: wdt0: watchdog@40010000 {
			compatible = "nordic,nrf-wdt"; /* in zephyr\dts\arm\nordic\nrf52840.dtsi:313 */
			reg = < 0x40010000 0x1000 >;   /* in zephyr\dts\arm\nordic\nrf52840.dtsi:314 */
			interrupts = < 0x10 0x1 >;     /* in zephyr\dts\arm\nordic\nrf52840.dtsi:315 */
			status = "okay";               /* in zephyr\dts\arm\nordic\nrf52840.dtsi:316 */
		};

		/* node '/soc/rtc@40011000' defined in zephyr\dts\arm\nordic\nrf52840.dtsi:319 */
		rtc1: rtc@40011000 {
			compatible = "nordic,nrf-rtc"; /* in zephyr\dts\arm\nordic\nrf52840.dtsi:320 */
			reg = < 0x40011000 0x1000 >;   /* in zephyr\dts\arm\nordic\nrf52840.dtsi:321 */
			cc-num = < 0x4 >;              /* in zephyr\dts\arm\nordic\nrf52840.dtsi:322 */
			interrupts = < 0x11 0x1 >;     /* in zephyr\dts\arm\nordic\nrf52840.dtsi:323 */
			status = "disabled";           /* in zephyr\dts\arm\nordic\nrf52840.dtsi:324 */
			clock-frequency = < 0x8000 >;  /* in zephyr\dts\arm\nordic\nrf52840.dtsi:325 */
			prescaler = < 0x1 >;           /* in zephyr\dts\arm\nordic\nrf52840.dtsi:326 */
		};

		/* node '/soc/qdec@40012000' defined in zephyr\dts\arm\nordic\nrf52840.dtsi:329 */
		qdec: qdec0: qdec@40012000 {
			compatible = "nordic,nrf-qdec"; /* in zephyr\dts\arm\nordic\nrf52840.dtsi:330 */
			reg = < 0x40012000 0x1000 >;    /* in zephyr\dts\arm\nordic\nrf52840.dtsi:331 */
			interrupts = < 0x12 0x1 >;      /* in zephyr\dts\arm\nordic\nrf52840.dtsi:332 */
			status = "disabled";            /* in zephyr\dts\arm\nordic\nrf52840.dtsi:333 */
		};

		/* node '/soc/comparator@40013000' defined in zephyr\dts\arm\nordic\nrf52840.dtsi:336 */
		comp: comparator@40013000 {
			compatible = "nordic,nrf-comp"; /* in zephyr\dts\arm\nordic\nrf52840.dtsi:341 */
			reg = < 0x40013000 0x1000 >;    /* in zephyr\dts\arm\nordic\nrf52840.dtsi:342 */
			interrupts = < 0x13 0x1 >;      /* in zephyr\dts\arm\nordic\nrf52840.dtsi:343 */
			status = "disabled";            /* in zephyr\dts\arm\nordic\nrf52840.dtsi:344 */
		};

		/* node '/soc/egu@40014000' defined in zephyr\dts\arm\nordic\nrf52840.dtsi:347 */
		egu0: swi0: egu@40014000 {
			compatible = "nordic,nrf-egu",
			             "nordic,nrf-swi"; /* in zephyr\dts\arm\nordic\nrf52840.dtsi:348 */
			reg = < 0x40014000 0x1000 >;   /* in zephyr\dts\arm\nordic\nrf52840.dtsi:349 */
			interrupts = < 0x14 0x1 >;     /* in zephyr\dts\arm\nordic\nrf52840.dtsi:350 */
			status = "okay";               /* in zephyr\dts\arm\nordic\nrf52840.dtsi:351 */
		};

		/* node '/soc/egu@40015000' defined in zephyr\dts\arm\nordic\nrf52840.dtsi:354 */
		egu1: swi1: egu@40015000 {
			compatible = "nordic,nrf-egu",
			             "nordic,nrf-swi"; /* in zephyr\dts\arm\nordic\nrf52840.dtsi:355 */
			reg = < 0x40015000 0x1000 >;   /* in zephyr\dts\arm\nordic\nrf52840.dtsi:356 */
			interrupts = < 0x15 0x1 >;     /* in zephyr\dts\arm\nordic\nrf52840.dtsi:357 */
			status = "okay";               /* in zephyr\dts\arm\nordic\nrf52840.dtsi:358 */
		};

		/* node '/soc/egu@40016000' defined in zephyr\dts\arm\nordic\nrf52840.dtsi:361 */
		egu2: swi2: egu@40016000 {
			compatible = "nordic,nrf-egu",
			             "nordic,nrf-swi"; /* in zephyr\dts\arm\nordic\nrf52840.dtsi:362 */
			reg = < 0x40016000 0x1000 >;   /* in zephyr\dts\arm\nordic\nrf52840.dtsi:363 */
			interrupts = < 0x16 0x1 >;     /* in zephyr\dts\arm\nordic\nrf52840.dtsi:364 */
			status = "okay";               /* in zephyr\dts\arm\nordic\nrf52840.dtsi:365 */
		};

		/* node '/soc/egu@40017000' defined in zephyr\dts\arm\nordic\nrf52840.dtsi:368 */
		egu3: swi3: egu@40017000 {
			compatible = "nordic,nrf-egu",
			             "nordic,nrf-swi"; /* in zephyr\dts\arm\nordic\nrf52840.dtsi:369 */
			reg = < 0x40017000 0x1000 >;   /* in zephyr\dts\arm\nordic\nrf52840.dtsi:370 */
			interrupts = < 0x17 0x1 >;     /* in zephyr\dts\arm\nordic\nrf52840.dtsi:371 */
			status = "okay";               /* in zephyr\dts\arm\nordic\nrf52840.dtsi:372 */
		};

		/* node '/soc/egu@40018000' defined in zephyr\dts\arm\nordic\nrf52840.dtsi:375 */
		egu4: swi4: egu@40018000 {
			compatible = "nordic,nrf-egu",
			             "nordic,nrf-swi"; /* in zephyr\dts\arm\nordic\nrf52840.dtsi:376 */
			reg = < 0x40018000 0x1000 >;   /* in zephyr\dts\arm\nordic\nrf52840.dtsi:377 */
			interrupts = < 0x18 0x1 >;     /* in zephyr\dts\arm\nordic\nrf52840.dtsi:378 */
			status = "okay";               /* in zephyr\dts\arm\nordic\nrf52840.dtsi:379 */
		};

		/* node '/soc/egu@40019000' defined in zephyr\dts\arm\nordic\nrf52840.dtsi:382 */
		egu5: swi5: egu@40019000 {
			compatible = "nordic,nrf-egu",
			             "nordic,nrf-swi"; /* in zephyr\dts\arm\nordic\nrf52840.dtsi:383 */
			reg = < 0x40019000 0x1000 >;   /* in zephyr\dts\arm\nordic\nrf52840.dtsi:384 */
			interrupts = < 0x19 0x1 >;     /* in zephyr\dts\arm\nordic\nrf52840.dtsi:385 */
			status = "okay";               /* in zephyr\dts\arm\nordic\nrf52840.dtsi:386 */
		};

		/* node '/soc/timer@4001a000' defined in zephyr\dts\arm\nordic\nrf52840.dtsi:389 */
		timer3: timer@4001a000 {
			compatible = "nordic,nrf-timer"; /* in zephyr\dts\arm\nordic\nrf52840.dtsi:390 */
			status = "disabled";             /* in zephyr\dts\arm\nordic\nrf52840.dtsi:391 */
			reg = < 0x4001a000 0x1000 >;     /* in zephyr\dts\arm\nordic\nrf52840.dtsi:392 */
			cc-num = < 0x6 >;                /* in zephyr\dts\arm\nordic\nrf52840.dtsi:393 */
			max-bit-width = < 0x20 >;        /* in zephyr\dts\arm\nordic\nrf52840.dtsi:394 */
			interrupts = < 0x1a 0x1 >;       /* in zephyr\dts\arm\nordic\nrf52840.dtsi:395 */
			prescaler = < 0x0 >;             /* in zephyr\dts\arm\nordic\nrf52840.dtsi:396 */
		};

		/* node '/soc/timer@4001b000' defined in zephyr\dts\arm\nordic\nrf52840.dtsi:399 */
		timer4: timer@4001b000 {
			compatible = "nordic,nrf-timer"; /* in zephyr\dts\arm\nordic\nrf52840.dtsi:400 */
			status = "disabled";             /* in zephyr\dts\arm\nordic\nrf52840.dtsi:401 */
			reg = < 0x4001b000 0x1000 >;     /* in zephyr\dts\arm\nordic\nrf52840.dtsi:402 */
			cc-num = < 0x6 >;                /* in zephyr\dts\arm\nordic\nrf52840.dtsi:403 */
			max-bit-width = < 0x20 >;        /* in zephyr\dts\arm\nordic\nrf52840.dtsi:404 */
			interrupts = < 0x1b 0x1 >;       /* in zephyr\dts\arm\nordic\nrf52840.dtsi:405 */
			prescaler = < 0x0 >;             /* in zephyr\dts\arm\nordic\nrf52840.dtsi:406 */
		};

		/* node '/soc/pwm@4001c000' defined in zephyr\dts\arm\nordic\nrf52840.dtsi:409 */
		pwm0: pwm@4001c000 {
			compatible = "nordic,nrf-pwm"; /* in zephyr\dts\arm\nordic\nrf52840.dtsi:410 */
			reg = < 0x4001c000 0x1000 >;   /* in zephyr\dts\arm\nordic\nrf52840.dtsi:411 */
			interrupts = < 0x1c 0x1 >;     /* in zephyr\dts\arm\nordic\nrf52840.dtsi:412 */
			#pwm-cells = < 0x3 >;          /* in zephyr\dts\arm\nordic\nrf52840.dtsi:414 */
			status = "okay";               /* in zephyr\boards\nordic\nrf52840dk\nrf52840dk_nrf52840.dts:219 */
			pinctrl-0 = < &pwm0_default >; /* in zephyr\boards\nordic\nrf52840dk\nrf52840dk_nrf52840.dts:220 */
			pinctrl-1 = < &pwm0_sleep >;   /* in zephyr\boards\nordic\nrf52840dk\nrf52840dk_nrf52840.dts:221 */
			pinctrl-names = "default",
			                "sleep";       /* in zephyr\boards\nordic\nrf52840dk\nrf52840dk_nrf52840.dts:222 */
			phandle = < 0x1a >;            /* in zephyr\boards\nordic\nrf52840dk\nrf52840dk_nrf52840.dts:56 */
		};

		/* node '/soc/pdm@4001d000' defined in zephyr\dts\arm\nordic\nrf52840.dtsi:417 */
		pdm0: pdm@4001d000 {
			compatible = "nordic,nrf-pdm"; /* in zephyr\dts\arm\nordic\nrf52840.dtsi:418 */
			reg = < 0x4001d000 0x1000 >;   /* in zephyr\dts\arm\nordic\nrf52840.dtsi:419 */
			interrupts = < 0x1d 0x1 >;     /* in zephyr\dts\arm\nordic\nrf52840.dtsi:420 */
			status = "disabled";           /* in zephyr\dts\arm\nordic\nrf52840.dtsi:421 */
		};

		/* node '/soc/acl@4001e000' defined in zephyr\dts\arm\nordic\nrf52840.dtsi:424 */
		acl: acl@4001e000 {
			compatible = "nordic,nrf-acl"; /* in zephyr\dts\arm\nordic\nrf52840.dtsi:425 */
			reg = < 0x4001e000 0x1000 >;   /* in zephyr\dts\arm\nordic\nrf52840.dtsi:426 */
			status = "okay";               /* in zephyr\dts\arm\nordic\nrf52840.dtsi:427 */
		};

		/* node '/soc/flash-controller@4001e000' defined in zephyr\dts\arm\nordic\nrf52840.dtsi:430 */
		flash_controller: flash-controller@4001e000 {
			compatible = "nordic,nrf52-flash-controller"; /* in zephyr\dts\arm\nordic\nrf52840.dtsi:431 */
			reg = < 0x4001e000 0x1000 >;                  /* in zephyr\dts\arm\nordic\nrf52840.dtsi:432 */
			ranges;                                       /* in zephyr\dts\arm\nordic\nrf52840.dtsi:433 */
			partial-erase;                                /* in zephyr\dts\arm\nordic\nrf52840.dtsi:434 */
			#address-cells = < 0x1 >;                     /* in zephyr\dts\arm\nordic\nrf52840.dtsi:435 */
			#size-cells = < 0x1 >;                        /* in zephyr\dts\arm\nordic\nrf52840.dtsi:436 */

			/* node '/soc/flash-controller@4001e000/flash@0' defined in zephyr\dts\arm\nordic\nrf52840.dtsi:438 */
			flash0: flash@0 {
				compatible = "soc-nv-flash";   /* in zephyr\dts\arm\nordic\nrf52840.dtsi:439 */
				erase-block-size = < 0x1000 >; /* in zephyr\dts\arm\nordic\nrf52840.dtsi:440 */
				write-block-size = < 0x4 >;    /* in zephyr\dts\arm\nordic\nrf52840.dtsi:441 */
				reg = < 0x0 0x100000 >;        /* in zephyr\dts\arm\nordic\nrf52840.dtsi:442 */
				ranges = < 0x0 0x0 0x100000 >; /* in zephyr\dts\arm\nordic\nrf52840.dtsi:443 */
				status = "okay";               /* in zephyr\dts\arm\nordic\nrf52840.dtsi:444 */
				#address-cells = < 0x1 >;      /* in zephyr\dts\arm\nordic\nrf52840.dtsi:445 */
				#size-cells = < 0x1 >;         /* in zephyr\dts\arm\nordic\nrf52840.dtsi:446 */

				/* node '/soc/flash-controller@4001e000/flash@0/partitions' defined in zephyr\dts\vendor\nordic\nrf52840_partition.dtsi:16 */
				partitions {
					ranges;                          /* in zephyr\dts\vendor\nordic\nrf52840_partition.dtsi:17 */
					compatible = "fixed-partitions"; /* in ..\..\Users\willh\Desktop\Fish_monitor\aquatic_biomonitor_fw\boards\nrf52840dk_nrf52840.overlay:47 */
					#address-cells = < 0x1 >;        /* in ..\..\Users\willh\Desktop\Fish_monitor\aquatic_biomonitor_fw\boards\nrf52840dk_nrf52840.overlay:48 */
					#size-cells = < 0x1 >;           /* in ..\..\Users\willh\Desktop\Fish_monitor\aquatic_biomonitor_fw\boards\nrf52840dk_nrf52840.overlay:49 */

					/* node '/soc/flash-controller@4001e000/flash@0/partitions/partition@0' defined in zephyr\dts\vendor\nordic\nrf52840_partition.dtsi:21 */
					boot_partition: partition@0 {
						compatible = "zephyr,mapped-partition"; /* in zephyr\dts\vendor\nordic\nrf52840_partition.dtsi:22 */
						label = "mcuboot";                      /* in zephyr\dts\vendor\nordic\nrf52840_partition.dtsi:23 */
						reg = < 0x0 0xc000 >;                   /* in zephyr\dts\vendor\nordic\nrf52840_partition.dtsi:24 */
					};

					/* node '/soc/flash-controller@4001e000/flash@0/partitions/partition@c000' defined in zephyr\dts\vendor\nordic\nrf52840_partition.dtsi:27 */
					slot0_partition: partition@c000 {
						compatible = "zephyr,mapped-partition"; /* in zephyr\dts\vendor\nordic\nrf52840_partition.dtsi:28 */
						label = "image-0";                      /* in zephyr\dts\vendor\nordic\nrf52840_partition.dtsi:29 */
						reg = < 0xc000 0x76000 >;               /* in zephyr\dts\vendor\nordic\nrf52840_partition.dtsi:30 */
					};

					/* node '/soc/flash-controller@4001e000/flash@0/partitions/partition@82000' defined in zephyr\dts\vendor\nordic\nrf52840_partition.dtsi:33 */
					slot1_partition: partition@82000 {
						compatible = "zephyr,mapped-partition"; /* in zephyr\dts\vendor\nordic\nrf52840_partition.dtsi:34 */
						label = "image-1";                      /* in zephyr\dts\vendor\nordic\nrf52840_partition.dtsi:35 */
						reg = < 0x82000 0x76000 >;              /* in zephyr\dts\vendor\nordic\nrf52840_partition.dtsi:36 */
					};

					/* node '/soc/flash-controller@4001e000/flash@0/partitions/partition@f8000' defined in zephyr\dts\vendor\nordic\nrf52840_partition.dtsi:48 */
					storage_partition: partition@f8000 {
						compatible = "zephyr,mapped-partition"; /* in zephyr\dts\vendor\nordic\nrf52840_partition.dtsi:49 */
						label = "storage";                      /* in ..\..\Users\willh\Desktop\Fish_monitor\aquatic_biomonitor_fw\boards\nrf52840dk_nrf52840.overlay:52 */
						reg = < 0xf8000 0x8000 >;               /* in ..\..\Users\willh\Desktop\Fish_monitor\aquatic_biomonitor_fw\boards\nrf52840dk_nrf52840.overlay:53 */
					};
				};
			};
		};

		/* node '/soc/ppi@4001f000' defined in zephyr\dts\arm\nordic\nrf52840.dtsi:450 */
		ppi: ppi@4001f000 {
			compatible = "nordic,nrf-ppi"; /* in zephyr\dts\arm\nordic\nrf52840.dtsi:451 */
			reg = < 0x4001f000 0x1000 >;   /* in zephyr\dts\arm\nordic\nrf52840.dtsi:452 */
			status = "okay";               /* in zephyr\dts\arm\nordic\nrf52840.dtsi:453 */
		};

		/* node '/soc/mwu@40020000' defined in zephyr\dts\arm\nordic\nrf52840.dtsi:456 */
		mwu: mwu@40020000 {
			compatible = "nordic,nrf-mwu"; /* in zephyr\dts\arm\nordic\nrf52840.dtsi:457 */
			reg = < 0x40020000 0x1000 >;   /* in zephyr\dts\arm\nordic\nrf52840.dtsi:458 */
			status = "okay";               /* in zephyr\dts\arm\nordic\nrf52840.dtsi:459 */
		};

		/* node '/soc/pwm@40021000' defined in zephyr\dts\arm\nordic\nrf52840.dtsi:462 */
		pwm1: pwm@40021000 {
			compatible = "nordic,nrf-pwm"; /* in zephyr\dts\arm\nordic\nrf52840.dtsi:463 */
			reg = < 0x40021000 0x1000 >;   /* in zephyr\dts\arm\nordic\nrf52840.dtsi:464 */
			interrupts = < 0x21 0x1 >;     /* in zephyr\dts\arm\nordic\nrf52840.dtsi:465 */
			status = "disabled";           /* in zephyr\dts\arm\nordic\nrf52840.dtsi:466 */
			#pwm-cells = < 0x3 >;          /* in zephyr\dts\arm\nordic\nrf52840.dtsi:467 */
		};

		/* node '/soc/pwm@40022000' defined in zephyr\dts\arm\nordic\nrf52840.dtsi:470 */
		pwm2: pwm@40022000 {
			compatible = "nordic,nrf-pwm"; /* in zephyr\dts\arm\nordic\nrf52840.dtsi:471 */
			reg = < 0x40022000 0x1000 >;   /* in zephyr\dts\arm\nordic\nrf52840.dtsi:472 */
			interrupts = < 0x22 0x1 >;     /* in zephyr\dts\arm\nordic\nrf52840.dtsi:473 */
			status = "disabled";           /* in zephyr\dts\arm\nordic\nrf52840.dtsi:474 */
			#pwm-cells = < 0x3 >;          /* in zephyr\dts\arm\nordic\nrf52840.dtsi:475 */
		};

		/* node '/soc/spi@40023000' defined in zephyr\dts\arm\nordic\nrf52840.dtsi:478 */
		spi2: spi@40023000 {
			#address-cells = < 0x1 >;       /* in zephyr\dts\arm\nordic\nrf52840.dtsi:487 */
			#size-cells = < 0x0 >;          /* in zephyr\dts\arm\nordic\nrf52840.dtsi:488 */
			reg = < 0x40023000 0x1000 >;    /* in zephyr\dts\arm\nordic\nrf52840.dtsi:489 */
			interrupts = < 0x23 0x1 >;      /* in zephyr\dts\arm\nordic\nrf52840.dtsi:490 */
			max-frequency = < 0x7a1200 >;   /* in zephyr\dts\arm\nordic\nrf52840.dtsi:491 */
			easydma-maxcnt-bits = < 0x10 >; /* in zephyr\dts\arm\nordic\nrf52840.dtsi:492 */
			compatible = "nordic,nrf-spi";  /* in zephyr\boards\nordic\nrf52840dk\nrf52840dk_nrf52840.dts:243 */
			status = "disabled";            /* in zephyr\boards\nordic\nrf52840dk\nrf52840dk_nrf52840.dts:244 */
			pinctrl-0 = < &spi2_default >;  /* in zephyr\boards\nordic\nrf52840dk\nrf52840dk_nrf52840.dts:245 */
			pinctrl-1 = < &spi2_sleep >;    /* in zephyr\boards\nordic\nrf52840dk\nrf52840dk_nrf52840.dts:246 */
			pinctrl-names = "default",
			                "sleep";        /* in zephyr\boards\nordic\nrf52840dk\nrf52840dk_nrf52840.dts:247 */
		};

		/* node '/soc/rtc@40024000' defined in zephyr\dts\arm\nordic\nrf52840.dtsi:496 */
		rtc2: rtc@40024000 {
			compatible = "nordic,nrf-rtc"; /* in zephyr\dts\arm\nordic\nrf52840.dtsi:497 */
			reg = < 0x40024000 0x1000 >;   /* in zephyr\dts\arm\nordic\nrf52840.dtsi:498 */
			cc-num = < 0x4 >;              /* in zephyr\dts\arm\nordic\nrf52840.dtsi:499 */
			interrupts = < 0x24 0x1 >;     /* in zephyr\dts\arm\nordic\nrf52840.dtsi:500 */
			status = "disabled";           /* in zephyr\dts\arm\nordic\nrf52840.dtsi:501 */
			clock-frequency = < 0x8000 >;  /* in zephyr\dts\arm\nordic\nrf52840.dtsi:502 */
			prescaler = < 0x1 >;           /* in zephyr\dts\arm\nordic\nrf52840.dtsi:503 */
		};

		/* node '/soc/i2s@40025000' defined in zephyr\dts\arm\nordic\nrf52840.dtsi:506 */
		i2s0: i2s@40025000 {
			compatible = "nordic,nrf-i2s"; /* in zephyr\dts\arm\nordic\nrf52840.dtsi:507 */
			#address-cells = < 0x1 >;      /* in zephyr\dts\arm\nordic\nrf52840.dtsi:508 */
			#size-cells = < 0x0 >;         /* in zephyr\dts\arm\nordic\nrf52840.dtsi:509 */
			reg = < 0x40025000 0x1000 >;   /* in zephyr\dts\arm\nordic\nrf52840.dtsi:510 */
			interrupts = < 0x25 0x1 >;     /* in zephyr\dts\arm\nordic\nrf52840.dtsi:511 */
			status = "disabled";           /* in zephyr\dts\arm\nordic\nrf52840.dtsi:512 */
		};

		/* node '/soc/usbd@40027000' defined in zephyr\dts\arm\nordic\nrf52840.dtsi:515 */
		usbd: zephyr_udc0: usbd@40027000 {
			reg = < 0x40027000 0x1000 >;    /* in zephyr\dts\arm\nordic\nrf52840.dtsi:517 */
			interrupts = < 0x27 0x1 >;      /* in zephyr\dts\arm\nordic\nrf52840.dtsi:518 */
			num-bidir-endpoints = < 0x1 >;  /* in zephyr\dts\arm\nordic\nrf52840.dtsi:519 */
			num-in-endpoints = < 0x7 >;     /* in zephyr\dts\arm\nordic\nrf52840.dtsi:520 */
			num-out-endpoints = < 0x7 >;    /* in zephyr\dts\arm\nordic\nrf52840.dtsi:521 */
			num-isoin-endpoints = < 0x1 >;  /* in zephyr\dts\arm\nordic\nrf52840.dtsi:522 */
			num-isoout-endpoints = < 0x1 >; /* in zephyr\dts\arm\nordic\nrf52840.dtsi:523 */
			compatible = "nordic,nrf-usbd"; /* in zephyr\boards\nordic\nrf52840dk\nrf52840dk_nrf52840.dts:289 */
			status = "okay";                /* in zephyr\boards\nordic\nrf52840dk\nrf52840dk_nrf52840.dts:290 */
		};

		/* node '/soc/uart@40028000' defined in zephyr\dts\arm\nordic\nrf52840.dtsi:527 */
		uart1: arduino_serial: uart@40028000 {
			compatible = "nordic,nrf-uarte"; /* in zephyr\dts\arm\nordic\nrf52840.dtsi:528 */
			reg = < 0x40028000 0x1000 >;     /* in zephyr\dts\arm\nordic\nrf52840.dtsi:529 */
			interrupts = < 0x28 0x1 >;       /* in zephyr\dts\arm\nordic\nrf52840.dtsi:530 */
			status = "disabled";             /* in zephyr\dts\arm\nordic\nrf52840.dtsi:531 */
			current-speed = < 0x1c200 >;     /* in zephyr\boards\nordic\nrf52840dk\nrf52840dk_nrf52840.dts:195 */
			pinctrl-0 = < &uart1_default >;  /* in zephyr\boards\nordic\nrf52840dk\nrf52840dk_nrf52840.dts:196 */
			pinctrl-1 = < &uart1_sleep >;    /* in zephyr\boards\nordic\nrf52840dk\nrf52840dk_nrf52840.dts:197 */
			pinctrl-names = "default",
			                "sleep";         /* in zephyr\boards\nordic\nrf52840dk\nrf52840dk_nrf52840.dts:198 */
		};

		/* node '/soc/qspi@40029000' defined in zephyr\dts\arm\nordic\nrf52840.dtsi:534 */
		qspi: qspi@40029000 {
			compatible = "nordic,nrf-qspi"; /* in zephyr\dts\arm\nordic\nrf52840.dtsi:535 */
			#address-cells = < 0x1 >;       /* in zephyr\dts\arm\nordic\nrf52840.dtsi:536 */
			#size-cells = < 0x0 >;          /* in zephyr\dts\arm\nordic\nrf52840.dtsi:537 */
			reg = < 0x40029000 0x1000 >,
			      < 0x12000000 0x8000000 >; /* in zephyr\dts\arm\nordic\nrf52840.dtsi:538 */
			reg-names = "qspi",
			            "qspi_mm";          /* in zephyr\dts\arm\nordic\nrf52840.dtsi:539 */
			interrupts = < 0x29 0x1 >;      /* in zephyr\dts\arm\nordic\nrf52840.dtsi:540 */
			status = "okay";                /* in zephyr\boards\nordic\nrf52840dk\nrf52840dk_nrf52840.dts:251 */
			pinctrl-0 = < &qspi_default >;  /* in zephyr\boards\nordic\nrf52840dk\nrf52840dk_nrf52840.dts:252 */
			pinctrl-1 = < &qspi_sleep >;    /* in zephyr\boards\nordic\nrf52840dk\nrf52840dk_nrf52840.dts:253 */
			pinctrl-names = "default",
			                "sleep";        /* in zephyr\boards\nordic\nrf52840dk\nrf52840dk_nrf52840.dts:254 */

			/* node '/soc/qspi@40029000/mx25r6435f@0' defined in zephyr\boards\nordic\nrf52840dk\nrf52840dk_nrf52840.dts:256 */
			mx25r64: mx25r6435f@0 {
				compatible = "nordic,qspi-nor";                                                               /* in zephyr\boards\nordic\nrf52840dk\nrf52840dk_nrf52840.dts:257 */
				reg = < 0x0 >;                                                                                /* in zephyr\boards\nordic\nrf52840dk\nrf52840dk_nrf52840.dts:258 */
				writeoc = "pp4io";                                                                            /* in zephyr\boards\nordic\nrf52840dk\nrf52840dk_nrf52840.dts:260 */
				readoc = "read4io";                                                                           /* in zephyr\boards\nordic\nrf52840dk\nrf52840dk_nrf52840.dts:262 */
				sck-frequency = < 0x7a1200 >;                                                                 /* in zephyr\boards\nordic\nrf52840dk\nrf52840dk_nrf52840.dts:263 */
				jedec-id = [ C2 28 17 ];                                                                      /* in zephyr\boards\nordic\nrf52840dk\nrf52840dk_nrf52840.dts:264 */
				sfdp-bfp = [ E5 20 F1 FF FF FF FF 03 44 EB 08 6B 08 3B 04 BB EE FF FF FF FF FF 00 FF FF FF 00
				             FF 0C 20 0F 52 10 D8 00 FF 23 72 F5 00 82 ED 04 CC 44 83 68 44 30 B0 30 B0 F7 C4
				             D5 5C 00 BE 29 FF F0 D0 FF FF ];                                                 /* in zephyr\boards\nordic\nrf52840dk\nrf52840dk_nrf52840.dts:265 */
				size = < 0x4000000 >;                                                                         /* in zephyr\boards\nordic\nrf52840dk\nrf52840dk_nrf52840.dts:269 */
				has-dpd;                                                                                      /* in zephyr\boards\nordic\nrf52840dk\nrf52840dk_nrf52840.dts:270 */
				t-enter-dpd = < 0x2710 >;                                                                     /* in zephyr\boards\nordic\nrf52840dk\nrf52840dk_nrf52840.dts:271 */
				t-exit-dpd = < 0x88b8 >;                                                                      /* in zephyr\boards\nordic\nrf52840dk\nrf52840dk_nrf52840.dts:272 */
			};
		};

		/* node '/soc/pwm@4002d000' defined in zephyr\dts\arm\nordic\nrf52840.dtsi:544 */
		pwm3: pwm@4002d000 {
			compatible = "nordic,nrf-pwm"; /* in zephyr\dts\arm\nordic\nrf52840.dtsi:545 */
			reg = < 0x4002d000 0x1000 >;   /* in zephyr\dts\arm\nordic\nrf52840.dtsi:546 */
			interrupts = < 0x2d 0x1 >;     /* in zephyr\dts\arm\nordic\nrf52840.dtsi:547 */
			status = "disabled";           /* in zephyr\dts\arm\nordic\nrf52840.dtsi:548 */
			#pwm-cells = < 0x3 >;          /* in zephyr\dts\arm\nordic\nrf52840.dtsi:549 */
		};

		/* node '/soc/spi@4002f000' defined in zephyr\dts\arm\nordic\nrf52840.dtsi:552 */
		spi3: arduino_spi: spi@4002f000 {
			compatible = "nordic,nrf-spim";          /* in zephyr\dts\arm\nordic\nrf52840.dtsi:553 */
			#address-cells = < 0x1 >;                /* in zephyr\dts\arm\nordic\nrf52840.dtsi:554 */
			#size-cells = < 0x0 >;                   /* in zephyr\dts\arm\nordic\nrf52840.dtsi:555 */
			reg = < 0x4002f000 0x1000 >;             /* in zephyr\dts\arm\nordic\nrf52840.dtsi:556 */
			interrupts = < 0x2f 0x1 >;               /* in zephyr\dts\arm\nordic\nrf52840.dtsi:557 */
			max-frequency = < 0x1e84800 >;           /* in zephyr\dts\arm\nordic\nrf52840.dtsi:558 */
			easydma-maxcnt-bits = < 0x10 >;          /* in zephyr\dts\arm\nordic\nrf52840.dtsi:559 */
			rx-delay-supported;                      /* in zephyr\dts\arm\nordic\nrf52840.dtsi:560 */
			rx-delay = < 0x2 >;                      /* in zephyr\dts\arm\nordic\nrf52840.dtsi:561 */
			status = "okay";                         /* in zephyr\boards\nordic\nrf52840dk\nrf52840dk_nrf52840.dts:277 */
			cs-gpios = < &arduino_header 0x10 0x1 >; /* in zephyr\boards\nordic\nrf52840dk\nrf52840dk_nrf52840.dts:278 */
			pinctrl-0 = < &spi3_default >;           /* in zephyr\boards\nordic\nrf52840dk\nrf52840dk_nrf52840.dts:279 */
			pinctrl-1 = < &spi3_sleep >;             /* in zephyr\boards\nordic\nrf52840dk\nrf52840dk_nrf52840.dts:280 */
			pinctrl-names = "default",
			                "sleep";                 /* in zephyr\boards\nordic\nrf52840dk\nrf52840dk_nrf52840.dts:281 */
		};

		/* node '/soc/gpio@50000000' defined in zephyr\dts\arm\nordic\nrf52840.dtsi:565 */
		gpio0: gpio@50000000 {
			compatible = "nordic,nrf-gpio";              /* in zephyr\dts\arm\nordic\nrf52840.dtsi:566 */
			gpio-controller;                             /* in zephyr\dts\arm\nordic\nrf52840.dtsi:567 */
			reg = < 0x50000000 0x200 0x50000500 0x300 >; /* in zephyr\dts\arm\nordic\nrf52840.dtsi:568 */
			#gpio-cells = < 0x2 >;                       /* in zephyr\dts\arm\nordic\nrf52840.dtsi:570 */
			port = < 0x0 >;                              /* in zephyr\dts\arm\nordic\nrf52840.dtsi:572 */
			gpiote-instance = < &gpiote >;               /* in zephyr\dts\arm\nordic\nrf52840.dtsi:573 */
			status = "okay";                             /* in zephyr\boards\nordic\nrf52840dk\nrf52840dk_nrf52840.dts:170 */
			gpio-reserved-ranges = < 0x0 0x2 >,
			                       < 0x6 0x1 >,
			                       < 0x8 0x3 >,
			                       < 0x11 0x7 >;         /* in zephyr\boards\nordic\nrf52840dk\nrf52840dk_nrf52840.dts:171 */
			gpio-line-names = "XL1",
			                  "XL2",
			                  "AREF",
			                  "A0",
			                  "A1",
			                  "RTS",
			                  "TXD",
			                  "CTS",
			                  "RXD",
			                  "NFC1",
			                  "NFC2",
			                  "BUTTON1",
			                  "BUTTON2",
			                  "LED1",
			                  "LED2",
			                  "LED3",
			                  "LED4",
			                  "QSPI CS",
			                  "RESET",
			                  "QSPI CLK",
			                  "QSPI DIO0",
			                  "QSPI DIO1",
			                  "QSPI DIO2",
			                  "QSPI DIO3",
			                  "BUTTON3",
			                  "BUTTON4",
			                  "SDA",
			                  "SCL",
			                  "A2",
			                  "A3",
			                  "A4",
			                  "A5";                      /* in zephyr\boards\nordic\nrf52840dk\nrf52840dk_nrf52840.dts:172 */
			phandle = < 0x19 >;                          /* in ..\..\Users\willh\Desktop\Fish_monitor\aquatic_biomonitor_fw\boards\nrf52840dk_nrf52840.overlay:10 */
		};

		/* node '/soc/gpio@50000300' defined in zephyr\dts\arm\nordic\nrf52840.dtsi:576 */
		gpio1: gpio@50000300 {
			compatible = "nordic,nrf-gpio";              /* in zephyr\dts\arm\nordic\nrf52840.dtsi:577 */
			gpio-controller;                             /* in zephyr\dts\arm\nordic\nrf52840.dtsi:578 */
			reg = < 0x50000300 0x200 0x50000800 0x300 >; /* in zephyr\dts\arm\nordic\nrf52840.dtsi:579 */
			#gpio-cells = < 0x2 >;                       /* in zephyr\dts\arm\nordic\nrf52840.dtsi:581 */
			ngpios = < 0x10 >;                           /* in zephyr\dts\arm\nordic\nrf52840.dtsi:582 */
			port = < 0x1 >;                              /* in zephyr\dts\arm\nordic\nrf52840.dtsi:584 */
			gpiote-instance = < &gpiote >;               /* in zephyr\dts\arm\nordic\nrf52840.dtsi:585 */
			status = "okay";                             /* in zephyr\boards\nordic\nrf52840dk\nrf52840dk_nrf52840.dts:180 */
			gpio-line-names = "",
			                  "D0",
			                  "D1",
			                  "D2",
			                  "D3",
			                  "D4",
			                  "D5",
			                  "D6",
			                  "D7",
			                  "",
			                  "D8",
			                  "D9",
			                  "D10",
			                  "D11",
			                  "D12",
			                  "D13";                     /* in zephyr\boards\nordic\nrf52840dk\nrf52840dk_nrf52840.dts:181 */
			phandle = < 0x1b >;                          /* in zephyr\boards\nordic\nrf52840dk\nrf52840dk_nrf52840.dts:93 */
		};

		/* node '/soc/crypto@5002a000' defined in zephyr\dts\arm\nordic\nrf52840.dtsi:588 */
		cryptocell: crypto@5002a000 {
			compatible = "arm,cryptocell-310"; /* in zephyr\dts\arm\nordic\nrf52840.dtsi:589 */
			reg = < 0x5002a000 0x1000 >,
			      < 0x5002b000 0x1000 >;       /* in zephyr\dts\arm\nordic\nrf52840.dtsi:590 */
			reg-names = "wrapper",
			            "core";                /* in zephyr\dts\arm\nordic\nrf52840.dtsi:591 */
			interrupts = < 0x2a 0x1 >;         /* in zephyr\dts\arm\nordic\nrf52840.dtsi:592 */
			status = "okay";                   /* in zephyr\dts\arm\nordic\nrf52840.dtsi:593 */
		};
	};

	/* node '/pin-controller' defined in zephyr\dts\vendor\nordic\nrf_common.dtsi:26 */
	pinctrl: pin-controller {
		compatible = "nordic,nrf-pinctrl"; /* in zephyr\dts\vendor\nordic\nrf_common.dtsi:31 */

		/* node '/pin-controller/uart0_default' defined in zephyr\boards\nordic\nrf52840dk\nrf52840dk_nrf52840-pinctrl.dtsi:7 */
		uart0_default: uart0_default {
			phandle = < 0x2 >; /* in zephyr\boards\nordic\nrf52840dk\nrf52840dk_nrf52840.dts:189 */

			/* node '/pin-controller/uart0_default/group1' defined in zephyr\boards\nordic\nrf52840dk\nrf52840dk_nrf52840-pinctrl.dtsi:8 */
			group1 {
				psels = < 0x6 >,
				        < 0x2000005 >; /* in zephyr\boards\nordic\nrf52840dk\nrf52840dk_nrf52840-pinctrl.dtsi:9 */
			};

			/* node '/pin-controller/uart0_default/group2' defined in zephyr\boards\nordic\nrf52840dk\nrf52840dk_nrf52840-pinctrl.dtsi:13 */
			group2 {
				psels = < 0x1000008 >,
				        < 0x3000007 >; /* in zephyr\boards\nordic\nrf52840dk\nrf52840dk_nrf52840-pinctrl.dtsi:14 */
				bias-pull-up;          /* in zephyr\boards\nordic\nrf52840dk\nrf52840dk_nrf52840-pinctrl.dtsi:16 */
			};
		};

		/* node '/pin-controller/uart0_sleep' defined in zephyr\boards\nordic\nrf52840dk\nrf52840dk_nrf52840-pinctrl.dtsi:20 */
		uart0_sleep: uart0_sleep {
			phandle = < 0x3 >; /* in zephyr\boards\nordic\nrf52840dk\nrf52840dk_nrf52840.dts:190 */

			/* node '/pin-controller/uart0_sleep/group1' defined in zephyr\boards\nordic\nrf52840dk\nrf52840dk_nrf52840-pinctrl.dtsi:21 */
			group1 {
				psels = < 0x1000008 >,
				        < 0x2000005 >,
				        < 0x3000007 >; /* in zephyr\boards\nordic\nrf52840dk\nrf52840dk_nrf52840-pinctrl.dtsi:22 */
				low-power-enable;      /* in zephyr\boards\nordic\nrf52840dk\nrf52840dk_nrf52840-pinctrl.dtsi:25 */
			};

			/* node '/pin-controller/uart0_sleep/group2' defined in zephyr\boards\nordic\nrf52840dk\nrf52840dk_nrf52840-pinctrl.dtsi:28 */
			group2 {
				psels = < 0x6 >;  /* in zephyr\boards\nordic\nrf52840dk\nrf52840dk_nrf52840-pinctrl.dtsi:29 */
				low-power-enable; /* in zephyr\boards\nordic\nrf52840dk\nrf52840dk_nrf52840-pinctrl.dtsi:30 */
				bias-pull-up;     /* in zephyr\boards\nordic\nrf52840dk\nrf52840dk_nrf52840-pinctrl.dtsi:31 */
			};
		};

		/* node '/pin-controller/uart1_default' defined in zephyr\boards\nordic\nrf52840dk\nrf52840dk_nrf52840-pinctrl.dtsi:35 */
		uart1_default: uart1_default {
			phandle = < 0x10 >; /* in zephyr\boards\nordic\nrf52840dk\nrf52840dk_nrf52840.dts:196 */

			/* node '/pin-controller/uart1_default/group1' defined in zephyr\boards\nordic\nrf52840dk\nrf52840dk_nrf52840-pinctrl.dtsi:36 */
			group1 {
				psels = < 0x1000021 >; /* in zephyr\boards\nordic\nrf52840dk\nrf52840dk_nrf52840-pinctrl.dtsi:37 */
				bias-pull-up;          /* in zephyr\boards\nordic\nrf52840dk\nrf52840dk_nrf52840-pinctrl.dtsi:38 */
			};

			/* node '/pin-controller/uart1_default/group2' defined in zephyr\boards\nordic\nrf52840dk\nrf52840dk_nrf52840-pinctrl.dtsi:41 */
			group2 {
				psels = < 0x22 >; /* in zephyr\boards\nordic\nrf52840dk\nrf52840dk_nrf52840-pinctrl.dtsi:42 */
			};
		};

		/* node '/pin-controller/uart1_sleep' defined in zephyr\boards\nordic\nrf52840dk\nrf52840dk_nrf52840-pinctrl.dtsi:46 */
		uart1_sleep: uart1_sleep {
			phandle = < 0x11 >; /* in zephyr\boards\nordic\nrf52840dk\nrf52840dk_nrf52840.dts:197 */

			/* node '/pin-controller/uart1_sleep/group1' defined in zephyr\boards\nordic\nrf52840dk\nrf52840dk_nrf52840-pinctrl.dtsi:47 */
			group1 {
				psels = < 0x1000021 >,
				        < 0x22 >;      /* in zephyr\boards\nordic\nrf52840dk\nrf52840dk_nrf52840-pinctrl.dtsi:48 */
				low-power-enable;      /* in zephyr\boards\nordic\nrf52840dk\nrf52840dk_nrf52840-pinctrl.dtsi:50 */
			};
		};

		/* node '/pin-controller/i2c0_default' defined in zephyr\boards\nordic\nrf52840dk\nrf52840dk_nrf52840-pinctrl.dtsi:54 */
		i2c0_default: i2c0_default {
			phandle = < 0x4 >; /* in zephyr\boards\nordic\nrf52840dk\nrf52840dk_nrf52840.dts:204 */

			/* node '/pin-controller/i2c0_default/group1' defined in zephyr\boards\nordic\nrf52840dk\nrf52840dk_nrf52840-pinctrl.dtsi:55 */
			group1 {
				psels = < 0xc00001a >,
				        < 0xb00001b >; /* in zephyr\boards\nordic\nrf52840dk\nrf52840dk_nrf52840-pinctrl.dtsi:56 */
			};
		};

		/* node '/pin-controller/i2c0_sleep' defined in zephyr\boards\nordic\nrf52840dk\nrf52840dk_nrf52840-pinctrl.dtsi:61 */
		i2c0_sleep: i2c0_sleep {
			phandle = < 0x5 >; /* in zephyr\boards\nordic\nrf52840dk\nrf52840dk_nrf52840.dts:205 */

			/* node '/pin-controller/i2c0_sleep/group1' defined in zephyr\boards\nordic\nrf52840dk\nrf52840dk_nrf52840-pinctrl.dtsi:62 */
			group1 {
				psels = < 0xc00001a >,
				        < 0xb00001b >; /* in zephyr\boards\nordic\nrf52840dk\nrf52840dk_nrf52840-pinctrl.dtsi:63 */
				low-power-enable;      /* in zephyr\boards\nordic\nrf52840dk\nrf52840dk_nrf52840-pinctrl.dtsi:65 */
			};
		};

		/* node '/pin-controller/i2c1_default' defined in zephyr\boards\nordic\nrf52840dk\nrf52840dk_nrf52840-pinctrl.dtsi:69 */
		i2c1_default: i2c1_default {
			phandle = < 0x8 >; /* in zephyr\boards\nordic\nrf52840dk\nrf52840dk_nrf52840.dts:213 */

			/* node '/pin-controller/i2c1_default/group1' defined in zephyr\boards\nordic\nrf52840dk\nrf52840dk_nrf52840-pinctrl.dtsi:70 */
			group1 {
				psels = < 0xc00001e >,
				        < 0xb00001f >; /* in zephyr\boards\nordic\nrf52840dk\nrf52840dk_nrf52840-pinctrl.dtsi:71 */
			};
		};

		/* node '/pin-controller/i2c1_sleep' defined in zephyr\boards\nordic\nrf52840dk\nrf52840dk_nrf52840-pinctrl.dtsi:76 */
		i2c1_sleep: i2c1_sleep {
			phandle = < 0x9 >; /* in zephyr\boards\nordic\nrf52840dk\nrf52840dk_nrf52840.dts:214 */

			/* node '/pin-controller/i2c1_sleep/group1' defined in zephyr\boards\nordic\nrf52840dk\nrf52840dk_nrf52840-pinctrl.dtsi:77 */
			group1 {
				psels = < 0xc00001e >,
				        < 0xb00001f >; /* in zephyr\boards\nordic\nrf52840dk\nrf52840dk_nrf52840-pinctrl.dtsi:78 */
				low-power-enable;      /* in zephyr\boards\nordic\nrf52840dk\nrf52840dk_nrf52840-pinctrl.dtsi:80 */
			};
		};

		/* node '/pin-controller/pwm0_default' defined in zephyr\boards\nordic\nrf52840dk\nrf52840dk_nrf52840-pinctrl.dtsi:84 */
		pwm0_default: pwm0_default {
			phandle = < 0xc >; /* in zephyr\boards\nordic\nrf52840dk\nrf52840dk_nrf52840.dts:220 */

			/* node '/pin-controller/pwm0_default/group1' defined in zephyr\boards\nordic\nrf52840dk\nrf52840dk_nrf52840-pinctrl.dtsi:85 */
			group1 {
				psels = < 0x1600000d >; /* in zephyr\boards\nordic\nrf52840dk\nrf52840dk_nrf52840-pinctrl.dtsi:86 */
				nordic,invert;          /* in zephyr\boards\nordic\nrf52840dk\nrf52840dk_nrf52840-pinctrl.dtsi:87 */
			};
		};

		/* node '/pin-controller/pwm0_sleep' defined in zephyr\boards\nordic\nrf52840dk\nrf52840dk_nrf52840-pinctrl.dtsi:91 */
		pwm0_sleep: pwm0_sleep {
			phandle = < 0xd >; /* in zephyr\boards\nordic\nrf52840dk\nrf52840dk_nrf52840.dts:221 */

			/* node '/pin-controller/pwm0_sleep/group1' defined in zephyr\boards\nordic\nrf52840dk\nrf52840dk_nrf52840-pinctrl.dtsi:92 */
			group1 {
				psels = < 0x1600000d >; /* in zephyr\boards\nordic\nrf52840dk\nrf52840dk_nrf52840-pinctrl.dtsi:93 */
				low-power-enable;       /* in zephyr\boards\nordic\nrf52840dk\nrf52840dk_nrf52840-pinctrl.dtsi:94 */
			};
		};

		/* node '/pin-controller/spi0_default' defined in zephyr\boards\nordic\nrf52840dk\nrf52840dk_nrf52840-pinctrl.dtsi:98 */
		spi0_default: spi0_default {
			phandle = < 0x6 >; /* in zephyr\boards\nordic\nrf52840dk\nrf52840dk_nrf52840.dts:229 */

			/* node '/pin-controller/spi0_default/group1' defined in zephyr\boards\nordic\nrf52840dk\nrf52840dk_nrf52840-pinctrl.dtsi:99 */
			group1 {
				psels = < 0x400001b >,
				        < 0x500001a >,
				        < 0x600001d >; /* in zephyr\boards\nordic\nrf52840dk\nrf52840dk_nrf52840-pinctrl.dtsi:100 */
			};
		};

		/* node '/pin-controller/spi0_sleep' defined in zephyr\boards\nordic\nrf52840dk\nrf52840dk_nrf52840-pinctrl.dtsi:106 */
		spi0_sleep: spi0_sleep {
			phandle = < 0x7 >; /* in zephyr\boards\nordic\nrf52840dk\nrf52840dk_nrf52840.dts:230 */

			/* node '/pin-controller/spi0_sleep/group1' defined in zephyr\boards\nordic\nrf52840dk\nrf52840dk_nrf52840-pinctrl.dtsi:107 */
			group1 {
				psels = < 0x400001b >,
				        < 0x500001a >,
				        < 0x600001d >; /* in zephyr\boards\nordic\nrf52840dk\nrf52840dk_nrf52840-pinctrl.dtsi:108 */
				low-power-enable;      /* in zephyr\boards\nordic\nrf52840dk\nrf52840dk_nrf52840-pinctrl.dtsi:111 */
			};
		};

		/* node '/pin-controller/spi1_default' defined in zephyr\boards\nordic\nrf52840dk\nrf52840dk_nrf52840-pinctrl.dtsi:115 */
		spi1_default: spi1_default {
			phandle = < 0xa >; /* in zephyr\boards\nordic\nrf52840dk\nrf52840dk_nrf52840.dts:237 */

			/* node '/pin-controller/spi1_default/group1' defined in zephyr\boards\nordic\nrf52840dk\nrf52840dk_nrf52840-pinctrl.dtsi:116 */
			group1 {
				psels = < 0x400001f >,
				        < 0x500001e >,
				        < 0x6000028 >; /* in zephyr\boards\nordic\nrf52840dk\nrf52840dk_nrf52840-pinctrl.dtsi:117 */
			};
		};

		/* node '/pin-controller/spi1_sleep' defined in zephyr\boards\nordic\nrf52840dk\nrf52840dk_nrf52840-pinctrl.dtsi:123 */
		spi1_sleep: spi1_sleep {
			phandle = < 0xb >; /* in zephyr\boards\nordic\nrf52840dk\nrf52840dk_nrf52840.dts:238 */

			/* node '/pin-controller/spi1_sleep/group1' defined in zephyr\boards\nordic\nrf52840dk\nrf52840dk_nrf52840-pinctrl.dtsi:124 */
			group1 {
				psels = < 0x400001f >,
				        < 0x500001e >,
				        < 0x6000028 >; /* in zephyr\boards\nordic\nrf52840dk\nrf52840dk_nrf52840-pinctrl.dtsi:125 */
				low-power-enable;      /* in zephyr\boards\nordic\nrf52840dk\nrf52840dk_nrf52840-pinctrl.dtsi:128 */
			};
		};

		/* node '/pin-controller/spi2_default' defined in zephyr\boards\nordic\nrf52840dk\nrf52840dk_nrf52840-pinctrl.dtsi:132 */
		spi2_default: spi2_default {
			phandle = < 0xe >; /* in zephyr\boards\nordic\nrf52840dk\nrf52840dk_nrf52840.dts:245 */

			/* node '/pin-controller/spi2_default/group1' defined in zephyr\boards\nordic\nrf52840dk\nrf52840dk_nrf52840-pinctrl.dtsi:133 */
			group1 {
				psels = < 0x4000013 >,
				        < 0x5000014 >,
				        < 0x6000015 >; /* in zephyr\boards\nordic\nrf52840dk\nrf52840dk_nrf52840-pinctrl.dtsi:134 */
			};
		};

		/* node '/pin-controller/spi2_sleep' defined in zephyr\boards\nordic\nrf52840dk\nrf52840dk_nrf52840-pinctrl.dtsi:140 */
		spi2_sleep: spi2_sleep {
			phandle = < 0xf >; /* in zephyr\boards\nordic\nrf52840dk\nrf52840dk_nrf52840.dts:246 */

			/* node '/pin-controller/spi2_sleep/group1' defined in zephyr\boards\nordic\nrf52840dk\nrf52840dk_nrf52840-pinctrl.dtsi:141 */
			group1 {
				psels = < 0x4000013 >,
				        < 0x5000014 >,
				        < 0x6000015 >; /* in zephyr\boards\nordic\nrf52840dk\nrf52840dk_nrf52840-pinctrl.dtsi:142 */
				low-power-enable;      /* in zephyr\boards\nordic\nrf52840dk\nrf52840dk_nrf52840-pinctrl.dtsi:145 */
			};
		};

		/* node '/pin-controller/qspi_default' defined in zephyr\boards\nordic\nrf52840dk\nrf52840dk_nrf52840-pinctrl.dtsi:149 */
		qspi_default: qspi_default {
			phandle = < 0x12 >; /* in zephyr\boards\nordic\nrf52840dk\nrf52840dk_nrf52840.dts:252 */

			/* node '/pin-controller/qspi_default/group1' defined in zephyr\boards\nordic\nrf52840dk\nrf52840dk_nrf52840-pinctrl.dtsi:150 */
			group1 {
				psels = < 0x1d000013 >,
				        < 0x1f000014 >,
				        < 0x20000015 >,
				        < 0x21000016 >,
				        < 0x22000017 >,
				        < 0x1e000011 >;      /* in zephyr\boards\nordic\nrf52840dk\nrf52840dk_nrf52840-pinctrl.dtsi:151 */
				nordic,drive-mode = < 0x3 >; /* in zephyr\boards\nordic\nrf52840dk\nrf52840dk_nrf52840-pinctrl.dtsi:157 */
			};
		};

		/* node '/pin-controller/qspi_sleep' defined in zephyr\boards\nordic\nrf52840dk\nrf52840dk_nrf52840-pinctrl.dtsi:161 */
		qspi_sleep: qspi_sleep {
			phandle = < 0x13 >; /* in zephyr\boards\nordic\nrf52840dk\nrf52840dk_nrf52840.dts:253 */

			/* node '/pin-controller/qspi_sleep/group1' defined in zephyr\boards\nordic\nrf52840dk\nrf52840dk_nrf52840-pinctrl.dtsi:162 */
			group1 {
				psels = < 0x1d000013 >,
				        < 0x1f000014 >,
				        < 0x20000015 >,
				        < 0x21000016 >,
				        < 0x22000017 >; /* in zephyr\boards\nordic\nrf52840dk\nrf52840dk_nrf52840-pinctrl.dtsi:163 */
				low-power-enable;       /* in zephyr\boards\nordic\nrf52840dk\nrf52840dk_nrf52840-pinctrl.dtsi:168 */
			};

			/* node '/pin-controller/qspi_sleep/group2' defined in zephyr\boards\nordic\nrf52840dk\nrf52840dk_nrf52840-pinctrl.dtsi:171 */
			group2 {
				psels = < 0x1e000011 >; /* in zephyr\boards\nordic\nrf52840dk\nrf52840dk_nrf52840-pinctrl.dtsi:172 */
				low-power-enable;       /* in zephyr\boards\nordic\nrf52840dk\nrf52840dk_nrf52840-pinctrl.dtsi:173 */
				bias-pull-up;           /* in zephyr\boards\nordic\nrf52840dk\nrf52840dk_nrf52840-pinctrl.dtsi:174 */
			};
		};

		/* node '/pin-controller/spi3_default' defined in zephyr\boards\nordic\nrf52840dk\nrf52840dk_nrf52840-pinctrl.dtsi:178 */
		spi3_default: spi3_default {
			phandle = < 0x15 >; /* in zephyr\boards\nordic\nrf52840dk\nrf52840dk_nrf52840.dts:279 */

			/* node '/pin-controller/spi3_default/group1' defined in zephyr\boards\nordic\nrf52840dk\nrf52840dk_nrf52840-pinctrl.dtsi:179 */
			group1 {
				psels = < 0x400002f >,
				        < 0x600002e >,
				        < 0x500002d >;       /* in zephyr\boards\nordic\nrf52840dk\nrf52840dk_nrf52840-pinctrl.dtsi:180 */
				nordic,drive-mode = < 0x3 >; /* in zephyr\boards\nordic\nrf52840dk\nrf52840dk_nrf52840-pinctrl.dtsi:183 */
			};
		};

		/* node '/pin-controller/spi3_sleep' defined in zephyr\boards\nordic\nrf52840dk\nrf52840dk_nrf52840-pinctrl.dtsi:187 */
		spi3_sleep: spi3_sleep {
			phandle = < 0x16 >; /* in zephyr\boards\nordic\nrf52840dk\nrf52840dk_nrf52840.dts:280 */

			/* node '/pin-controller/spi3_sleep/group1' defined in zephyr\boards\nordic\nrf52840dk\nrf52840dk_nrf52840-pinctrl.dtsi:188 */
			group1 {
				psels = < 0x400002f >,
				        < 0x600002e >,
				        < 0x500002d >; /* in zephyr\boards\nordic\nrf52840dk\nrf52840dk_nrf52840-pinctrl.dtsi:189 */
				low-power-enable;      /* in zephyr\boards\nordic\nrf52840dk\nrf52840dk_nrf52840-pinctrl.dtsi:192 */
			};
		};
	};

	/* node '/entropy_bt_hci' defined in zephyr\dts\vendor\nordic\nrf_common.dtsi:34 */
	rng_hci: entropy_bt_hci {
		compatible = "zephyr,bt-hci-entropy"; /* in zephyr\dts\vendor\nordic\nrf_common.dtsi:35 */
		status = "disabled";                  /* in zephyr\dts\vendor\nordic\nrf_common.dtsi:36 */
	};

	/* node '/sw-pwm' defined in zephyr\dts\vendor\nordic\nrf_common.dtsi:39 */
	sw_pwm: sw-pwm {
		compatible = "nordic,nrf-sw-pwm"; /* in zephyr\dts\vendor\nordic\nrf_common.dtsi:40 */
		status = "disabled";              /* in zephyr\dts\vendor\nordic\nrf_common.dtsi:41 */
		generator = < &timer1 >;          /* in zephyr\dts\vendor\nordic\nrf_common.dtsi:42 */
		clock-prescaler = < 0x0 >;        /* in zephyr\dts\vendor\nordic\nrf_common.dtsi:43 */
		#pwm-cells = < 0x3 >;             /* in zephyr\dts\vendor\nordic\nrf_common.dtsi:44 */
	};

	/* node '/cpus' defined in zephyr\dts\arm\nordic\nrf52840.dtsi:19 */
	cpus {
		#address-cells = < 0x1 >; /* in zephyr\dts\arm\nordic\nrf52840.dtsi:20 */
		#size-cells = < 0x0 >;    /* in zephyr\dts\arm\nordic\nrf52840.dtsi:21 */

		/* node '/cpus/cpu@0' defined in zephyr\dts\arm\nordic\nrf52840.dtsi:23 */
		cpu@0 {
			device_type = "cpu";           /* in zephyr\dts\arm\nordic\nrf52840.dtsi:24 */
			compatible = "arm,cortex-m4f"; /* in zephyr\dts\arm\nordic\nrf52840.dtsi:25 */
			reg = < 0x0 >;                 /* in zephyr\dts\arm\nordic\nrf52840.dtsi:26 */
			#address-cells = < 0x1 >;      /* in zephyr\dts\arm\nordic\nrf52840.dtsi:27 */
			#size-cells = < 0x1 >;         /* in zephyr\dts\arm\nordic\nrf52840.dtsi:28 */

			/* node '/cpus/cpu@0/itm@e0000000' defined in zephyr\dts\arm\nordic\nrf52840.dtsi:30 */
			itm: itm@e0000000 {
				compatible = "arm,armv7m-itm";     /* in zephyr\dts\arm\nordic\nrf52840.dtsi:31 */
				reg = < 0xe0000000 0x1000 >;       /* in zephyr\dts\arm\nordic\nrf52840.dtsi:32 */
				swo-ref-frequency = < 0x1e84800 >; /* in zephyr\dts\arm\nordic\nrf52840.dtsi:33 */
			};
		};
	};

	/* node '/clocks' defined in zephyr\dts\arm\nordic\nrf52840.dtsi:38 */
	clocks {

		/* node '/clocks/hfxo' defined in zephyr\dts\arm\nordic\nrf52840.dtsi:39 */
		hfxo: hfxo {
			compatible = "nordic,nrf52-hfxo"; /* in zephyr\dts\arm\nordic\nrf52840.dtsi:40 */
			clock-frequency = < 0x3d09000 >;  /* in zephyr\dts\arm\nordic\nrf52840.dtsi:41 */
			startup-time-us = < 0x578 >;      /* in zephyr\dts\arm\nordic\nrf52840.dtsi:42 */
			#clock-cells = < 0x0 >;           /* in zephyr\dts\arm\nordic\nrf52840.dtsi:43 */
		};
	};

	/* node '/leds' defined in zephyr\boards\nordic\nrf52840dk\nrf52840dk_nrf52840.dts:28 */
	leds {
		compatible = "gpio-leds"; /* in ..\..\Users\willh\Desktop\Fish_monitor\aquatic_biomonitor_fw\boards\nrf52840dk_nrf52840.overlay:8 */

		/* node '/leds/led_0' defined in zephyr\boards\nordic\nrf52840dk\nrf52840dk_nrf52840.dts:31 */
		led0: led_status: led_0 {
			gpios = < &gpio0 0x6 0x0 >; /* in ..\..\Users\willh\Desktop\Fish_monitor\aquatic_biomonitor_fw\boards\nrf52840dk_nrf52840.overlay:10 */
			label = "STATUS_LED";       /* in ..\..\Users\willh\Desktop\Fish_monitor\aquatic_biomonitor_fw\boards\nrf52840dk_nrf52840.overlay:11 */
		};

		/* node '/leds/led_1' defined in zephyr\boards\nordic\nrf52840dk\nrf52840dk_nrf52840.dts:36 */
		led1: led_1 {
			gpios = < &gpio0 0xe 0x1 >; /* in zephyr\boards\nordic\nrf52840dk\nrf52840dk_nrf52840.dts:37 */
			label = "Green LED 1";      /* in zephyr\boards\nordic\nrf52840dk\nrf52840dk_nrf52840.dts:38 */
		};

		/* node '/leds/led_2' defined in zephyr\boards\nordic\nrf52840dk\nrf52840dk_nrf52840.dts:41 */
		led2: led_2 {
			gpios = < &gpio0 0xf 0x1 >; /* in zephyr\boards\nordic\nrf52840dk\nrf52840dk_nrf52840.dts:42 */
			label = "Green LED 2";      /* in zephyr\boards\nordic\nrf52840dk\nrf52840dk_nrf52840.dts:43 */
		};

		/* node '/leds/led_3' defined in zephyr\boards\nordic\nrf52840dk\nrf52840dk_nrf52840.dts:46 */
		led3: led_3 {
			gpios = < &gpio0 0x10 0x1 >; /* in zephyr\boards\nordic\nrf52840dk\nrf52840dk_nrf52840.dts:47 */
			label = "Green LED 3";       /* in zephyr\boards\nordic\nrf52840dk\nrf52840dk_nrf52840.dts:48 */
		};
	};

	/* node '/pwmleds' defined in zephyr\boards\nordic\nrf52840dk\nrf52840dk_nrf52840.dts:52 */
	pwmleds {
		compatible = "pwm-leds"; /* in zephyr\boards\nordic\nrf52840dk\nrf52840dk_nrf52840.dts:53 */

		/* node '/pwmleds/pwm_led_0' defined in zephyr\boards\nordic\nrf52840dk\nrf52840dk_nrf52840.dts:55 */
		pwm_led0: pwm_led_0 {
			pwms = < &pwm0 0x0 0x1312d00 0x1 >; /* in zephyr\boards\nordic\nrf52840dk\nrf52840dk_nrf52840.dts:56 */
		};
	};

	/* node '/buttons' defined in zephyr\boards\nordic\nrf52840dk\nrf52840dk_nrf52840.dts:60 */
	buttons {
		compatible = "gpio-keys"; /* in zephyr\boards\nordic\nrf52840dk\nrf52840dk_nrf52840.dts:61 */

		/* node '/buttons/button_0' defined in zephyr\boards\nordic\nrf52840dk\nrf52840dk_nrf52840.dts:63 */
		button0: button_0 {
			gpios = < &gpio0 0xb 0x11 >;    /* in zephyr\boards\nordic\nrf52840dk\nrf52840dk_nrf52840.dts:64 */
			label = "Push button switch 0"; /* in zephyr\boards\nordic\nrf52840dk\nrf52840dk_nrf52840.dts:65 */
			zephyr,code = < 0xb >;          /* in zephyr\boards\nordic\nrf52840dk\nrf52840dk_nrf52840.dts:66 */
		};

		/* node '/buttons/button_1' defined in zephyr\boards\nordic\nrf52840dk\nrf52840dk_nrf52840.dts:69 */
		button1: button_1 {
			gpios = < &gpio0 0xc 0x11 >;    /* in zephyr\boards\nordic\nrf52840dk\nrf52840dk_nrf52840.dts:70 */
			label = "Push button switch 1"; /* in zephyr\boards\nordic\nrf52840dk\nrf52840dk_nrf52840.dts:71 */
			zephyr,code = < 0x2 >;          /* in zephyr\boards\nordic\nrf52840dk\nrf52840dk_nrf52840.dts:72 */
		};

		/* node '/buttons/button_2' defined in zephyr\boards\nordic\nrf52840dk\nrf52840dk_nrf52840.dts:75 */
		button2: button_2 {
			gpios = < &gpio0 0x18 0x11 >;   /* in zephyr\boards\nordic\nrf52840dk\nrf52840dk_nrf52840.dts:76 */
			label = "Push button switch 2"; /* in zephyr\boards\nordic\nrf52840dk\nrf52840dk_nrf52840.dts:77 */
			zephyr,code = < 0x3 >;          /* in zephyr\boards\nordic\nrf52840dk\nrf52840dk_nrf52840.dts:78 */
		};

		/* node '/buttons/button_3' defined in zephyr\boards\nordic\nrf52840dk\nrf52840dk_nrf52840.dts:81 */
		button3: button_3 {
			gpios = < &gpio0 0x19 0x11 >;   /* in zephyr\boards\nordic\nrf52840dk\nrf52840dk_nrf52840.dts:82 */
			label = "Push button switch 3"; /* in zephyr\boards\nordic\nrf52840dk\nrf52840dk_nrf52840.dts:83 */
			zephyr,code = < 0x4 >;          /* in zephyr\boards\nordic\nrf52840dk\nrf52840dk_nrf52840.dts:84 */
		};
	};

	/* node '/connector' defined in zephyr\boards\nordic\nrf52840dk\nrf52840dk_nrf52840.dts:88 */
	arduino_header: connector {
		compatible = "arduino-header-r3";          /* in zephyr\boards\nordic\nrf52840dk\nrf52840dk_nrf52840.dts:89 */
		#gpio-cells = < 0x2 >;                     /* in zephyr\boards\nordic\nrf52840dk\nrf52840dk_nrf52840.dts:90 */
		gpio-map-mask = < 0xffffffff 0xffffffc0 >; /* in zephyr\boards\nordic\nrf52840dk\nrf52840dk_nrf52840.dts:91 */
		gpio-map-pass-thru = < 0x0 0x3f >;         /* in zephyr\boards\nordic\nrf52840dk\nrf52840dk_nrf52840.dts:92 */
		gpio-map = < 0x0 0x0 &gpio0 0x3 0x0 >,
		           < 0x1 0x0 &gpio0 0x4 0x0 >,
		           < 0x2 0x0 &gpio0 0x1c 0x0 >,
		           < 0x3 0x0 &gpio0 0x1d 0x0 >,
		           < 0x4 0x0 &gpio0 0x1e 0x0 >,
		           < 0x5 0x0 &gpio0 0x1f 0x0 >,
		           < 0x6 0x0 &gpio1 0x1 0x0 >,
		           < 0x7 0x0 &gpio1 0x2 0x0 >,
		           < 0x8 0x0 &gpio1 0x3 0x0 >,
		           < 0x9 0x0 &gpio1 0x4 0x0 >,
		           < 0xa 0x0 &gpio1 0x5 0x0 >,
		           < 0xb 0x0 &gpio1 0x6 0x0 >,
		           < 0xc 0x0 &gpio1 0x7 0x0 >,
		           < 0xd 0x0 &gpio1 0x8 0x0 >,
		           < 0xe 0x0 &gpio1 0xa 0x0 >,
		           < 0xf 0x0 &gpio1 0xb 0x0 >,
		           < 0x10 0x0 &gpio1 0xc 0x0 >,
		           < 0x11 0x0 &gpio1 0xd 0x0 >,
		           < 0x12 0x0 &gpio1 0xe 0x0 >,
		           < 0x13 0x0 &gpio1 0xf 0x0 >,
		           < 0x14 0x0 &gpio0 0x1a 0x0 >,
		           < 0x15 0x0 &gpio0 0x1b 0x0 >;   /* in zephyr\boards\nordic\nrf52840dk\nrf52840dk_nrf52840.dts:93 */
		phandle = < 0x14 >;                        /* in zephyr\boards\nordic\nrf52840dk\nrf52840dk_nrf52840.dts:278 */
	};

	/* node '/analog-connector' defined in zephyr\boards\nordic\nrf52840dk\nrf52840dk_nrf52840.dts:117 */
	arduino_adc: analog-connector {
		compatible = "arduino,uno-adc";    /* in zephyr\boards\nordic\nrf52840dk\nrf52840dk_nrf52840.dts:118 */
		#io-channel-cells = < 0x1 >;       /* in zephyr\boards\nordic\nrf52840dk\nrf52840dk_nrf52840.dts:119 */
		io-channel-map = < 0x0 &adc 0x1 >,
		                 < 0x1 &adc 0x2 >,
		                 < 0x2 &adc 0x4 >,
		                 < 0x3 &adc 0x5 >,
		                 < 0x4 &adc 0x6 >,
		                 < 0x5 &adc 0x7 >; /* in zephyr\boards\nordic\nrf52840dk\nrf52840dk_nrf52840.dts:120 */
	};

	/* node '/zephyr,user' defined in ..\..\Users\willh\Desktop\Fish_monitor\aquatic_biomonitor_fw\boards\nrf52840dk_nrf52840.overlay:2 */
	zephyr,user {
		io-channels = < &adc 0x0 >;     /* in ..\..\Users\willh\Desktop\Fish_monitor\aquatic_biomonitor_fw\boards\nrf52840dk_nrf52840.overlay:3 */
		sdn-gpios = < &gpio0 0xd 0x0 >; /* in ..\..\Users\willh\Desktop\Fish_monitor\aquatic_biomonitor_fw\boards\nrf52840dk_nrf52840.overlay:4 */
	};
};
